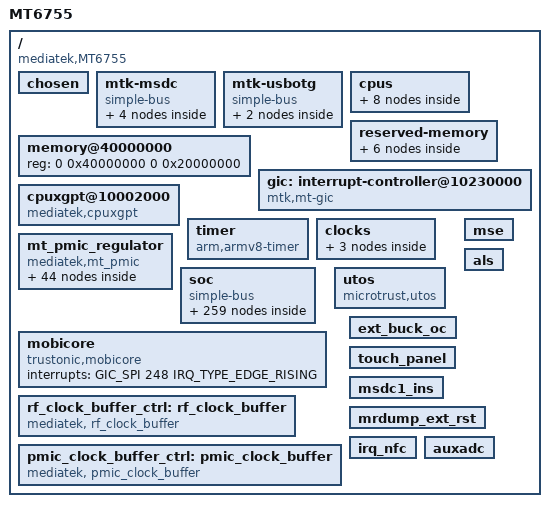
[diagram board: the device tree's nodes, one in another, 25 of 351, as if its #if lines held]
/*
 * Mediatek's MT6755 SoC device tree source
 *
 * Copyright (c) 2013 MediaTek Co., Ltd.
 *              http://www.mediatek.com
 *
 */

#include <dt-bindings/clock/mt6755-clk.h>
#include <dt-bindings/interrupt-controller/arm-gic.h>
#include <dt-bindings/interrupt-controller/irq.h>
#include "mt6755-pinfunc.h"
#include <generated/autoconf.h>

/ {
	model = "MT6755";
	compatible = "mediatek,MT6755";
	interrupt-parent = <&gic>;
	#address-cells = <2>;
	#size-cells = <2>;

	/* chosen */
	chosen {
		bootargs = "console=tty0 console=ttyMT0,921600n1 root=/dev/ram initrd=0x44000000,0x4B434E loglevel=8";
	};

	/* Do not put any bus before mtk-msdc, because it should be mtk-msdc.0 for partition device node usage */
	mtk-msdc {
		compatible = "simple-bus";
		#address-cells = <1>;
		#size-cells = <1>;
		ranges = <0 0 0 0xffffffff>;

		msdc0@11230000 {
			compatible = "mediatek,msdc0";
			reg = <0x11230000 0x10000  /* MSDC0_BASE   */
			       0x10001e84 0x2>;    /* FPGA PWR_GPIO, PWR_GPIO_EO */
			interrupts = <GIC_SPI 79 IRQ_TYPE_LEVEL_LOW>;
			clocks = <&infrasys INFRA_MSDC0>;
			clock-names = "MSDC0-CLOCK";
		};

		msdc1@11240000 {
			compatible = "mediatek,msdc1";
			reg = <0x11240000 0x10000>;
			interrupts = <GIC_SPI 80 IRQ_TYPE_LEVEL_LOW>;
			clocks = <&infrasys INFRA_MSDC1>;
			clock-names = "MSDC1-CLOCK";
		};

		msdc2@11250000 {
			compatible = "mediatek,msdc2";
			reg = <0x11250000 0x10000>;
			interrupts = <GIC_SPI 81 IRQ_TYPE_LEVEL_LOW>;
			clocks = <&infrasys INFRA_MSDC2>;
			clock-names = "MSDC2-CLOCK";
		};

		msdc3@11260000 {
			compatible = "mediatek,msdc3";
			reg = <0x11260000 0x10000>;
			interrupts = <GIC_SPI 82 IRQ_TYPE_LEVEL_LOW>;
			clocks = <&infrasys INFRA_MSDC3>;
			clock-names = "MSDC3-CLOCK";
		};

	};
	/* Do not put any bus before mtk-usbotg, because it should be mtk-usbotg.1 for partition device node usage */
	mtk-usbotg {
		compatible = "simple-bus";
		#address-cells = <1>;
		#size-cells = <1>;
		ranges = <0 0 0 0xffffffff>;
		usb3_xhci@11270000 {
			compatible = "mediatek,usb3_xhci";
			reg = <0x11270000 0x10000>, <0x11280000 0x10000>, <0x11290000 0x10000>;
			reg-names = "ssusb_base", "ssusb_sif", "ssusb_sif2";
			interrupts = <GIC_SPI 123 IRQ_TYPE_LEVEL_LOW>;
			interrupt-names = "xhci";
			eint_usb_iddig@23{
				compatible = "mediatek,usb_iddig_bi_eint";
				interrupt-parent = <&eintc>;
				interrupts = <23 IRQ_TYPE_LEVEL_LOW>;
				debounce = <23 0>;
			};
		};
	};

	cpus {
		#address-cells = <1>;
		#size-cells = <0>;

		cpu0: cpu@000 {
			device_type = "cpu";
			compatible = "arm,cortex-a53";
			reg = <0x000>;
			enable-method = "mt-boot";
			cpu-release-addr = <0x0 0x40000200>;
			clock-frequency = <1144000000>;
		};

		cpu1: cpu@001 {
			device_type = "cpu";
			compatible = "arm,cortex-a53";
			reg = <0x001>;
			enable-method = "mt-boot";
			cpu-release-addr = <0x0 0x40000200>;
			clock-frequency = <1144000000>;
		};

		cpu2: cpu@002 {
			device_type = "cpu";
			compatible = "arm,cortex-a53";
			reg = <0x002>;
			enable-method = "mt-boot";
			cpu-release-addr = <0x0 0x40000200>;
			clock-frequency = <1144000000>;
		};

		cpu3: cpu@003 {
			device_type = "cpu";
			compatible = "arm,cortex-a53";
			reg = <0x003>;
			enable-method = "mt-boot";
			cpu-release-addr = <0x0 0x40000200>;
			clock-frequency = <1144000000>;
		};
		cpu4: cpu@100 {
			device_type = "cpu";
			compatible = "arm,cortex-a53";
			reg = <0x100>;
			enable-method = "mt-boot";
			cpu-release-addr = <0x0 0x40000200>;
			clock-frequency = <1950000000>;
		};

		cpu5: cpu@101 {
			device_type = "cpu";
			compatible = "arm,cortex-a53";
			reg = <0x101>;
			enable-method = "mt-boot";
			cpu-release-addr = <0x0 0x40000200>;
			clock-frequency = <1950000000>;
		};

		cpu6: cpu@102 {
			device_type = "cpu";
			compatible = "arm,cortex-a53";
			reg = <0x102>;
			enable-method = "mt-boot";
			cpu-release-addr = <0x0 0x40000200>;
			clock-frequency = <1950000000>;
		};

		cpu7: cpu@103 {
			device_type = "cpu";
			compatible = "arm,cortex-a53";
			reg = <0x103>;
			enable-method = "mt-boot";
			cpu-release-addr = <0x0 0x40000200>;
			clock-frequency = <1950000000>;

		};
	};

	memory@40000000 {
		device_type = "memory";
		reg = <0 0x40000000 0 0x20000000>;
	};

	reserved-memory {
		#address-cells = <2>;
		#size-cells = <2>;
		ranges;

		/* reserve 256KB at DRAM start + 70MB */
		atf-reserved-memory@44600000 {
			compatible = "mediatek,mt6755-atf-reserved-memory";
			no-map;
			reg = <0 0x44600000 0 0x40000>;
		};

		reserve-memory-ccci_md1 {
			compatible = "mediatek,reserve-memory-ccci_md1";
			no-map;
			size = <0 0x8000000>; /* md_size+smem_size */
			alignment = <0 0x2000000>;
			alloc-ranges = <0 0x40000000 0 0xC0000000>;
		};

		reserve-memory-ccci_share {
			compatible = "mediatek,reserve-memory-ccci_share";
			no-map;
			size = <0 0x600000>; /* md_size+smem_size */
			alignment = <0 0x4000000>;
			alloc-ranges = <0 0x40000000 0 0xC0000000>;
		};

		consys-reserve-memory {
			compatible = "mediatek,consys-reserve-memory";
			no-map;
			size = <0 0x200000>;
			alignment = <0 0x200000>;
		};

		spm-reserve-memory {
			compatible = "mediatek,spm-reserve-memory";
			no-map;
			size = <0 0xe000>; /* PCM_FIRMWARE_SIZE * DYNA_LOAD_PCM_MAX = 8K * 7 */
			alignment = <0 0x10000>;
			alloc-ranges = <0 0x40000000 0 0x80000000>;
		};

		pstore-reserved-memory@44410000 {
			compatible = "mediatek,pstore";
			reg = <0 0x44410000 0 0xe0000>;
		};
	};

	gic: interrupt-controller@10230000 {
		compatible = "mtk,mt-gic";
		#interrupt-cells = <3>;
		#address-cells = <0>;
		interrupt-controller;
		reg = <0 0x10231000 0 0x1000>,
		      <0 0x10232000 0 0x1000>,
		      <0 0x10200620 0 0x1000>;
		interrupts = <1 9 0xf04>;

	};

	cpuxgpt@10002000 {
		compatible = "mediatek,cpuxgpt";
		reg = <0 0x10200000 0 0x1000>;
		interrupts = <GIC_SPI 64 IRQ_TYPE_LEVEL_HIGH>,
			<GIC_SPI 65 IRQ_TYPE_LEVEL_HIGH>,
			<GIC_SPI 66 IRQ_TYPE_LEVEL_HIGH>,
			<GIC_SPI 67 IRQ_TYPE_LEVEL_HIGH>,
			<GIC_SPI 68 IRQ_TYPE_LEVEL_HIGH>,
			<GIC_SPI 69 IRQ_TYPE_LEVEL_HIGH>,
			<GIC_SPI 70 IRQ_TYPE_LEVEL_HIGH>,
			<GIC_SPI 71 IRQ_TYPE_LEVEL_HIGH>;
	};

	timer {
		compatible = "arm,armv8-timer";
		interrupts = <GIC_PPI 13 IRQ_TYPE_LEVEL_LOW>,
			<GIC_PPI 14 IRQ_TYPE_LEVEL_LOW>,
			<GIC_PPI 11 IRQ_TYPE_LEVEL_LOW>,
			<GIC_PPI 10 IRQ_TYPE_LEVEL_LOW>;
			clock-frequency = <13000000>;
	};

	clocks {
		clk_null: clk_null {
			compatible = "fixed-clock";
			#clock-cells = <0>;
			clock-frequency = <0>;
		};

		clk26m: clk26m {
			compatible = "fixed-clock";
			#clock-cells = <0>;
			clock-frequency = <26000000>;
		};

		clk32k: clk32k {
			compatible = "fixed-clock";
			#clock-cells = <0>;
			clock-frequency = <32000>;
		};
	};

	mt_pmic_regulator {
		compatible = "mediatek,mt_pmic";
		/*reg = <0x01>*/
		buck_regulators {
			compatible = "mediatek,mt_pmic_buck_regulators";
			mt_pmic_vcore_buck_reg: buck_vcore {
				regulator-name = "vcore";
				regulator-min-microvolt = <600000>;
				regulator-max-microvolt = <1393750>;
				regulator-ramp-delay = <6250>;
				regulator-enable-ramp-delay = <180>;
			};
			mt_pmic_vgpu_buck_reg: buck_vgpu {
				regulator-name = "vgpu";
				regulator-min-microvolt = <600000>;
				regulator-max-microvolt = <1393750>;
				regulator-ramp-delay = <6250>;
				regulator-enable-ramp-delay = <180>;
				regulator-always-on;
				regulator-boot-on;
			};
			mt_pmic_vmodem_buck_reg: buck_vmodem {
				regulator-name = "vmodem";
				regulator-min-microvolt = <600000>;
				regulator-max-microvolt = <1393750>;
				regulator-ramp-delay = <6250>;
				regulator-enable-ramp-delay = <180>;
				regulator-always-on;
				regulator-boot-on;
			};
			mt_pmic_vmd1_buck_reg: buck_vmd1 {
				regulator-name = "vmd1";
				regulator-min-microvolt = <600000>;
				regulator-max-microvolt = <1393750>;
				regulator-ramp-delay = <6250>;
				regulator-enable-ramp-delay = <180>;
				regulator-always-on;
				regulator-boot-on;
			};
			mt_pmic_vsram_md_buck_reg: buck_vsram_md {
				regulator-name = "vsram_md";
				regulator-min-microvolt = <600000>;
				regulator-max-microvolt = <1393750>;
				regulator-ramp-delay = <6250>;
				regulator-enable-ramp-delay = <180>;
				regulator-always-on;
				regulator-boot-on;
			};
			mt_pmic_vs1_buck_reg: buck_vs1 {
				regulator-name = "vs1";
				regulator-min-microvolt = <600000>;
				regulator-max-microvolt = <1393750>;
				regulator-ramp-delay = <6250>;
				regulator-enable-ramp-delay = <180>;
				regulator-always-on;
				regulator-boot-on;
			};
			mt_pmic_vs2_buck_reg: buck_vs2 {
				regulator-name = "vs2";
				regulator-min-microvolt = <600000>;
				regulator-max-microvolt = <1393750>;
				regulator-ramp-delay = <6250>;
				regulator-enable-ramp-delay = <180>;
				regulator-always-on;
				regulator-boot-on;
			};
			mt_pmic_vpa_buck_reg: buck_vpa {
				regulator-name = "vpa";
				regulator-min-microvolt = <600000>;
				regulator-max-microvolt = <1393750>;
				regulator-ramp-delay = <6250>;
				regulator-enable-ramp-delay = <180>;
				regulator-always-on;
				regulator-boot-on;
			};
			mt_pmic_vsram_proc_buck_reg: buck_vsram_proc {
				regulator-name = "vsram_proc";
				regulator-min-microvolt = <600000>;
				regulator-max-microvolt = <1393750>;
				regulator-ramp-delay = <6250>;
				regulator-enable-ramp-delay = <180>;
				regulator-always-on;
				regulator-boot-on;
			};
		};	/* End of buck_regulators */
		ldo_regulators {
			compatible = "mediatek,mt_pmic_ldo_regulators";
			mt_pmic_va18_ldo_reg: ldo_va18 {
				regulator-name = "va18";
				regulator-min-microvolt = <1800000>;
				regulator-max-microvolt = <1800000>;
				regulator-enable-ramp-delay = <264>;
				regulator-boot-on;
			};
			mt_pmic_vtcxo24_ldo_reg: ldo_vtcxo24 {
				regulator-name = "vtcxo24";
				regulator-min-microvolt = <1800000>;
				regulator-max-microvolt = <2800000>;
				regulator-enable-ramp-delay = <110>;
				regulator-boot-on;
			};
			mt_pmic_vtcxo28_ldo_reg: ldo_vtcxo28 {
				regulator-name = "vtcxo28";
				regulator-min-microvolt = <1800000>;
				regulator-max-microvolt = <2800000>;
				regulator-enable-ramp-delay = <110>;
			};
			mt_pmic_vcn28_ldo_reg: ldo_vcn28 {
				regulator-name = "vcn28";
				regulator-min-microvolt = <1800000>;
				regulator-max-microvolt = <2800000>;
				regulator-enable-ramp-delay = <264>;
			};
			mt_pmic_vcama_ldo_reg: ldo_vcama {
				regulator-name = "vcama";
				regulator-min-microvolt = <1500000>;
				regulator-max-microvolt = <2800000>;
				regulator-enable-ramp-delay = <264>;
			};
			mt_pmic_vusb33_ldo_reg: ldo_vusb33 {
				regulator-name = "vusb33";
				regulator-min-microvolt = <3300000>;
				regulator-max-microvolt = <3300000>;
				regulator-enable-ramp-delay = <264>;
				regulator-boot-on;
			};
			mt_pmic_vsim1_ldo_reg: ldo_vsim1 {
				regulator-name = "vsim1";
				regulator-min-microvolt = <1700000>;
				regulator-max-microvolt = <3100000>;
				regulator-enable-ramp-delay = <264>;
			};
			mt_pmic_vsim2_ldo_reg: ldo_vsim2 {
				regulator-name = "vsim2";
				regulator-min-microvolt = <1700000>;
				regulator-max-microvolt = <3100000>;
				regulator-enable-ramp-delay = <264>;
			};
			mt_pmic_vemc_ldo_reg: ldo_vemc {
				regulator-name = "vemc_3v3";
				regulator-min-microvolt = <3000000>;
				regulator-max-microvolt = <3300000>;
				regulator-enable-ramp-delay = <44>;
				regulator-boot-on;
			};
			mt_pmic_vmch_ldo_reg: ldo_vmch {
				regulator-name = "vmch";
				regulator-min-microvolt = <3000000>;
				regulator-max-microvolt = <3300000>;
				regulator-enable-ramp-delay = <44>;
				regulator-boot-on;
			};
			mt_pmic_vio28_ldo_reg: ldo_vio28 {
				regulator-name = "vio28";
				regulator-min-microvolt = <2800000>;
				regulator-max-microvolt = <2800000>;
				regulator-enable-ramp-delay = <264>;
				regulator-boot-on;
			};
			mt_pmic_vibr_ldo_reg: ldo_vibr {
				regulator-name = "vibr";
				regulator-min-microvolt = <1200000>;
				regulator-max-microvolt = <3300000>;
				regulator-enable-ramp-delay = <44>;
			};
			mt_pmic_vcamd_ldo_reg: ldo_vcamd {
				regulator-name = "vcamd";
				regulator-min-microvolt = <900000>;
				regulator-max-microvolt = <1210000>;
				regulator-enable-ramp-delay = <264>;
			};
			mt_pmic_vrf18_ldo_reg: ldo_vrf18 {
				regulator-name = "vrf18";
				regulator-min-microvolt = <1000000>;
				regulator-max-microvolt = <1810000>;
				regulator-enable-ramp-delay = <220>;
			};
			mt_pmic_vio18_ldo_reg: ldo_vio18 {
				regulator-name = "vio18";
				regulator-min-microvolt = <1800000>;
				regulator-max-microvolt = <1800000>;
				regulator-enable-ramp-delay = <264>;
				regulator-boot-on;
			};
			mt_pmic_vcn18_ldo_reg: ldo_vcn18 {
				regulator-name = "vcn18";
				regulator-min-microvolt = <1800000>;
				regulator-max-microvolt = <1800000>;
				regulator-enable-ramp-delay = <44>;
			};
			mt_pmic_vcamio_ldo_reg: ldo_vcamio {
				regulator-name = "vcamio";
				regulator-min-microvolt = <1200000>;
				regulator-max-microvolt = <1800000>;
				regulator-enable-ramp-delay = <220>;
			};
			mt_pmic_vsram_proc_ldo_reg: ldo_vsram_proc {
				regulator-name = "vsram_proc";
				regulator-min-microvolt = <600000>;
				regulator-max-microvolt = <1393750>;
				regulator-enable-ramp-delay = <220>;
				regulator-boot-on;
			};
			mt_pmic_vxo22_ldo_reg: ldo_vxo22 {
				regulator-name = "vxo22";
				regulator-min-microvolt = <1800000>;
				regulator-max-microvolt = <2800000>;
				regulator-enable-ramp-delay = <110>;
				regulator-boot-on;
			};
			mt_pmic_vrf12_ldo_reg: ldo_vrf12 {
				regulator-name = "vrf12";
				regulator-min-microvolt = <900000>;
				regulator-max-microvolt = <1200000>;
				regulator-enable-ramp-delay = <220>;
			};
			mt_pmic_va10_ldo_reg: ldo_va10 {
				regulator-name = "va10";
				regulator-min-microvolt = <900000>;
				regulator-max-microvolt = <1800000>;
				regulator-enable-ramp-delay = <264>;
				regulator-boot-on;
			};
			mt_pmic_vdram_ldo_reg: ldo_vdram {
				regulator-name = "vdram";
				regulator-min-microvolt = <900000>;
				regulator-max-microvolt = <1210000>;
				regulator-enable-ramp-delay = <264>;
				regulator-boot-on;
			};
			mt_pmic_vmipi_ldo_reg: ldo_vmipi {
				regulator-name = "vmipi";
				regulator-min-microvolt = <900000>;
				regulator-max-microvolt = <1800000>;
				regulator-enable-ramp-delay = <264>;
			};
			mt_pmic_vgp3_ldo_reg: ldo_vgp3 {
				regulator-name = "vgp3";
				regulator-min-microvolt = <1000000>;
				regulator-max-microvolt = <1810000>;
				regulator-enable-ramp-delay = <264>;
			};
			mt_pmic_vbif28_ldo_reg: ldo_vbif28 {
				regulator-name = "vbif28";
				regulator-min-microvolt = <2800000>;
				regulator-max-microvolt = <2800000>;
				regulator-enable-ramp-delay = <264>;
			};
			mt_pmic_vefuse_ldo_reg: ldo_vefuse {
				regulator-name = "vefuse";
				regulator-min-microvolt = <1200000>;
				regulator-max-microvolt = <2200000>;
				regulator-enable-ramp-delay = <264>;
			};
			mt_pmic_vcn33_bt_ldo_reg: ldo_vcn33_bt {
				regulator-name = "vcn33_bt";
				regulator-min-microvolt = <3300000>;
				regulator-max-microvolt = <3600000>;
				regulator-enable-ramp-delay = <264>;
			};
			mt_pmic_vcn33_wifi_ldo_reg: ldo_vcn33_wifi {
				regulator-name = "vcn33_wifi";
				regulator-min-microvolt = <3300000>;
				regulator-max-microvolt = <3600000>;
				regulator-enable-ramp-delay = <264>;
			};
			mt_pmic_vldo28_ldo_reg: ldo_vldo28 {
				regulator-name = "vldo28";
				regulator-min-microvolt = <2800000>;
				regulator-max-microvolt = <2800000>;
				regulator-enable-ramp-delay = <264>;
			};
			mt_pmic_vmc_ldo_reg: ldo_vmc {
				regulator-name = "vmc";
				regulator-min-microvolt = <1200000>;
				regulator-max-microvolt = <3300000>;
				regulator-enable-ramp-delay = <44>;
				regulator-boot-on;
			};
			mt_pmic_vldo28_0_ldo_reg: ldo_vldo28_0 {
				regulator-name = "vldo28_0";
				regulator-min-microvolt = <2800000>;
				regulator-max-microvolt = <2800000>;
				regulator-enable-ramp-delay = <264>;
			};
			mt_pmic_vldo28_1_ldo_reg: ldo_vldo28_1 {
				regulator-name = "vldo28_1";
				regulator-min-microvolt = <2800000>;
				regulator-max-microvolt = <2800000>;
				regulator-enable-ramp-delay = <264>;
			};
		};/* End of ldo_regulators */

		regulators_supply {
			compatible = "mediatek,mt_pmic_regulator_supply";
			va18-supply = <&mt_pmic_va18_ldo_reg>;
			vtcxo24-supply = <&mt_pmic_vtcxo24_ldo_reg>;
			vtcxo28-supply = <&mt_pmic_vtcxo28_ldo_reg>;
			vsim1-supply = <&mt_pmic_vsim1_ldo_reg>;
			vsim2-supply = <&mt_pmic_vsim2_ldo_reg>;
			vemc-supply = <&mt_pmic_vemc_ldo_reg>;
			vmch-supply = <&mt_pmic_vmch_ldo_reg>;
			vmc-supply = <&mt_pmic_vmc_ldo_reg>;
			vio28-supply = <&mt_pmic_vio28_ldo_reg>;
			vibr-supply = <&mt_pmic_vibr_ldo_reg>;
			vrf18-supply = <&mt_pmic_vrf18_ldo_reg>;
			vio18-supply = <&mt_pmic_vio18_ldo_reg>;
			vsram_proc-supply = <&mt_pmic_vsram_proc_ldo_reg>;
			vxo22-supply = <&mt_pmic_vxo22_ldo_reg>;
			vrf12-supply = <&mt_pmic_vrf12_ldo_reg>;
			vdram-supply = <&mt_pmic_vdram_ldo_reg>;
			vmipi-supply = <&mt_pmic_vmipi_ldo_reg>;
			vbif28-supply = <&mt_pmic_vbif28_ldo_reg>;
			vefuse-supply = <&mt_pmic_vefuse_ldo_reg>;
		};/* End of regulators_supply */
	};/* End of mt_pmic_regulator */

	soc {
		compatible = "simple-bus";
		#address-cells = <1>;
		#size-cells = <1>;
		ranges;

		vcore_dvfs@0011cf80 {
			compatible = "mediatek,vcore_dvfs";
			reg = <0x0011cf80 0x80>;
			eint_spm_vcorefs_end@154 {
				compatible = "mediatek,spm_vcorefs_err_eint";
				interrupt-parent = <&eintc>;
				interrupts = <154 IRQ_TYPE_LEVEL_HIGH>;
				debounce = <154 0>;
			};
		};

		chipid@08000000 {
			compatible = "mediatek,chipid";
			reg = <0x08000000 0x0004>,
				<0x08000004 0x0004>,
				<0x08000008 0x0004>,
				<0x0800000c 0x0004>;
		};

		topckgen: topckgen@10000000 {
			compatible = "mediatek,mt6755-topckgen";
			reg = <0x10000000 0x1000>;
			#clock-cells = <1>;
		};

		topckgen@1000000 {
			compatible = "mediatek,topckgen";
			reg = <0x10000000 0x1000>;
		};

		scpsys: scpsys@10001000 {
			compatible = "mediatek,mt6755-scpsys";
			reg = <0x10001000 0x1000>, <0x10006000 0x1000>;
			#clock-cells = <1>;
		};

		infrasys: infrasys@10001000 {
			compatible = "mediatek,mt6755-infrasys";
			reg = <0x10001000 0x1000>;
			#clock-cells = <1>;
		};

		infracfg_ao@10001000 {
			compatible = "mediatek,infracfg_ao";
			reg = <0x10001000 0x1000>;
			interrupts = <GIC_SPI 136 IRQ_TYPE_EDGE_RISING>;
		};

		iocfg_0@10002000 {
			compatible = "mediatek,iocfg_0";
			reg = <0x10002000 0x1000>;
		};

		syscfg_pctl_a: syscfg_pctl_a@10002000 {
			compatible = "mediatek,mt6755-pctl-a-syscfg", "syscon";
			reg = <0 0x10002000 0 0x1000>;
		};

		iocfg_1@10002200 {
			compatible = "mediatek,iocfg_1";
			reg = <0x10002200 0x200>;
		};

		iocfg_2@10002400 {
			compatible = "mediatek,iocfg_2";
			reg = <0x10002400 0x200>;
		};

		iocfg_3@10002600 {
			compatible = "mediatek,iocfg_3";
			reg = <0x10002600 0x200>;
		};

		iocfg_4@10002800 {
			compatible = "mediatek,iocfg_4";
			reg = <0x10002800 0x200>;
		};

		iocfg_5@10002a00 {
			compatible = "mediatek,iocfg_5";
			reg = <0x10002a00 0x200>;
		};

		perisys: perisys@10003000 {
			compatible = "mediatek,mt6755-perisys";
			reg = <0x10003000 0x1000>;
			#clock-cells = <1>;
		};

		pericfg@10003000 {
			compatible = "mediatek,pericfg";
			reg = <0x10003000 0x1000>;
		};

		dramc0@10004000 {
			compatible = "mediatek,dramc0";
			reg = <0x10004000 0x1000>;
			interrupts = <GIC_SPI 149 IRQ_TYPE_EDGE_FALLING>;
		};

		pio: pinctrl@10005000 {
			compatible = "mediatek,mt6755-pinctrl";
			reg = <0 0x10005000 0 0x1000>;
			mediatek,pctl-regmap = <&syscfg_pctl_a>;
			gpio-controller;
			#gpio-cells = <2>;
			interrupt-controller;
			#interrupt-cells = <2>;
		};

		gpio@10005000 {
			compatible = "mediatek,gpio";
			reg = <0x10005000 0x1000>;
		};

		sleep@10006000 {
			compatible = "mediatek,sleep";
			reg = <0x10006000 0x1000>;
			interrupts = <GIC_SPI 165 IRQ_TYPE_LEVEL_LOW>,
				     <GIC_SPI 166 IRQ_TYPE_LEVEL_LOW>,
				     <GIC_SPI 167 IRQ_TYPE_LEVEL_LOW>,
				     <GIC_SPI 168 IRQ_TYPE_LEVEL_LOW>,
				     <GIC_SPI 169 IRQ_TYPE_LEVEL_LOW>,
				     <GIC_SPI 170 IRQ_TYPE_LEVEL_LOW>,
				     <GIC_SPI 171 IRQ_TYPE_LEVEL_LOW>,
				     <GIC_SPI 172 IRQ_TYPE_LEVEL_LOW>;
			clocks = <&infrasys INFRA_I2C3>;
			clock-names = "i2c3-main";
			clock-div = <10>;
			#address-cells = <1>;
			#size-cells = <0>;
			eint_spm_vcorefs_start@152 {
				compatible = "mediatek,spm_vcorefs_start_eint";
				interrupt-parent = <&eintc>;
				interrupts = <152 IRQ_TYPE_LEVEL_HIGH>;
				debounce = <152 0>;
			};

			eint_spm_vcorefs_end@153 {
				compatible = "mediatek,spm_vcorefs_end_eint";
				interrupt-parent = <&eintc>;
				interrupts = <153 IRQ_TYPE_LEVEL_HIGH>;
				debounce = <153 0>;
			};

		};

		toprgu@10007000 {
			compatible = "mediatek,toprgu";
			reg = <0x10007000 0x1000>;
			interrupts = <GIC_SPI 128 IRQ_TYPE_EDGE_FALLING>;
		};

		apxgpt@10008000 {
			compatible = "mediatek,apxgpt";
			reg = <0x10008000 0x1000>;
			interrupts = <GIC_SPI 154 IRQ_TYPE_LEVEL_LOW>;
			clock-frequency = <13000000>;
		};

		rsvd@10009000 {
			compatible = "mediatek,rsvd";
			reg = <0x10009000 0x1000>;
		};

		sej@1000a000 {
			compatible = "mediatek,hacc";
			reg = <0x1000a000 0x1000>;
			interrupts = <GIC_SPI 173 IRQ_TYPE_LEVEL_LOW>;
			clocks = <&infrasys INFRA_SEJ>;
			clock-names = "hacc-main";

		};

		eintc: eintc@1000b000 {
			compatible = "mtk,mt-eic";
			reg = <0x1000b000 0x1000>;
			interrupts = <GIC_SPI 155 IRQ_TYPE_LEVEL_HIGH>;
			max_deint_cnt = <4>;
                        deint_possible_irq = <191 192 193 194>;

			#interrupt-cells = <2>;
			interrupt-controller;

			max_eint_num = <160>;
			mapping_table_entry = <0>;
			debtime_setting_entry = <10>;
			debtime_setting_array = <0 128>,
						<1 256>,
						<2 512>,
						<3 1024>,
						<4 16384>,
						<5 32768>,
						<6 65536>,
						<7 131072>,
						<8 262144>,
						<9 524288>;

		};

		apmixedsys: apmixedsys@1000c000 {
			compatible = "mediatek,mt6755-apmixedsys";
			reg = <0x1000c000 0x1000>;
			#clock-cells = <1>;
		};

		apmixed@1000c000 {
			compatible = "mediatek,apmixed";
			reg = <0x1000c000 0xf00>;
		};

		fhctl@1000cf00 {
			compatible = "mediatek,fhctl";
			reg = <0x1000cf00 0x100>;
		};

		pwrap@1000d000 {
			compatible = "mediatek,pwrap";
			reg = <0x1000d000 0x1000>;
			interrupts = <GIC_SPI 163 IRQ_TYPE_LEVEL_HIGH>;

			pmic: mt6351 {
				compatible = "mediatek,mt6351-pmic";
				interrupt-parent = <&eintc>;
				interrupts = <150 4>;
				debounce = <150 1000>;
				interrupt-controller;
			};
		};

		devapc_ao: devapc_ao@1000e000 {
			compatible = "mediatek,devapc_ao";
			reg = <0x1000e000 0x1000>;
		};

		ddrphy@1000f000 {
			compatible = "mediatek,ddrphy";
			reg = <0x1000f000 0x1000>;
		};

		keypad: keypad@10010000 {
			compatible = "mediatek,mt6755-keypad", "mediatek,kp";
			reg = <0x10010000 0x1000>;
			interrupts = <GIC_SPI 164 IRQ_TYPE_EDGE_FALLING>;
		};

		topmisc@10011000 {
			compatible = "mediatek,topmisc";
			reg = <0x10011000 0x1000>;
		};

		mdcldma:mdcldma@10014000 {
			compatible = "mediatek,mdcldma";
			reg = 	<0x10014000 0x1e00>, /*AP_CLDMA_AO*/
				<0x10015000 0x1e00>, /*MD_CLDMA_AO*/
				<0x1021b000 0x1e00>, /*AP_CLDMA_PDN*/
				<0x1021c000 0x1e00>, /*MD_CLDMA_PDN*/
				<0x10209000 0x1000>, /*AP_CCIF_BASE*/
				<0x1020a000 0x1000>; /*MD_CCIF_BASE*/
			interrupts = <GIC_SPI 222 IRQ_TYPE_LEVEL_HIGH>, /*IRQ_CLDMA*/
				     <GIC_SPI 139 IRQ_TYPE_LEVEL_LOW>, /*IRQ_CCIF*/
				     <GIC_SPI 223 IRQ_TYPE_EDGE_FALLING>; /*IRQ_MDWDT*/
			mediatek,md_id = <0>;
			mediatek,cldma_capability = <6>;
			mediatek,md_smem_size = <0x100000>; /* md share memory size */
			clocks = <&scpsys SCP_SYS_MD1>;
			clock-names = "scp-sys-md1-main";
		};

		cpu_dbgapb {
			compatible = "mediatek,dbg_debug";
			num = <8>;
			reg =  <0x10810000 0x1000
				0x10910000 0x1000
				0x10A10000 0x1000
				0x10B10000 0x1000
				0x10C10000 0x1000
				0x10D10000 0x1000
				0x10E10000 0x1000
				0x10F10000 0x1000>;
		};

		aes_top0@10016000 {
			compatible = "mediatek,aes_top0";
			reg = <0x10016000 0x1000>;
		};

		aes_top1@10017000 {
			compatible = "mediatek,aes_top1";
			reg = <0x10017000 0x1000>;
		};

		modem_temp_share@10018000 {
			compatible = "mediatek,modem_temp_share";
			reg = <0x10018000 0x1000>;
		};

		scp_sram@10020000 {
			compatible = "mediatek,scp_sram";
			reg = <0x10020000 0x60000>;
		};

		dbgapb_base@1011a000{
			compatible = "mediatek,dbgapb_base";
			reg = <0x1011a000 0x100>;/* MD debug register */
		};

		mcucfg@10200000 {
			compatible = "mediatek,mcucfg";
			reg = <0x10200000 0x1000>;
			interrupts = <GIC_SPI 0 IRQ_TYPE_LEVEL_LOW>;
		};

		lastbus@10200000 {
			compatible = "mediatek,lastbus";
			reg = <0x10200000 0x1000>,
				<0x10003000 0x1000>;
		};

		infracfg@10201000 {
			compatible = "mediatek,infracfg";
			reg = <0x10201000 0x1000>;
		};

		sramrom@10202000 {
			compatible = "mediatek,sramrom";
			reg = <0x10202000 0x1000>;
		};

		emi@10203000 {
			compatible = "mediatek,emi";
			reg = <0x10203000 0x1000>;
			interrupts = <GIC_SPI 135 IRQ_TYPE_EDGE_FALLING>;
		};

		met_emi: met_emi@10203000 {
			compatible = "mediatek,met_emi";
			reg = <0x10203000 0x1000>;
		};

		sys_cirq@10204000 {
			compatible = "mediatek,sys_cirq";
			reg = <0x10204000 0x1000>;
			interrupts = <GIC_SPI 240 IRQ_TYPE_LEVEL_LOW>;
			cirq_num = <168>;
			spi_start_offset = <72>;
		};

		m4u@10205000 {
                        cell-index = <0>;
			compatible = "mediatek,m4u";
			reg = <0x10205000 0x1000>;
			interrupts = <GIC_SPI 147 IRQ_TYPE_LEVEL_LOW>;
			clocks = <&mmsys MM_DISP0_SMI_COMMON>,
				<&mmsys MM_DISP0_SMI_LARB0>,
				<&vdecsys VDEC0_VDEC>,
				<&vdecsys VDEC1_LARB>,
				<&imgsys IMG_IMAGE_LARB2_SMI>,
				<&vencsys VENC_VENC>,
				<&vencsys VENC_LARB>;
                        clock-names = "smi_common",
                                      "m4u_disp0_smi_larb0",
                                      "m4u_vdec0_vdec",
                                      "m4u_vdec1_larb",
                                      "m4u_img_image_larb2_smi",
                                      "m4u_venc_venc",
                                      "m4u_venc_larb";
		};

		efusec: efusec@10206000 {
			compatible = "mediatek,efusec";
			reg = <0x10206000 0x1000>;
		};

		devapc: devapc@10207000 {
			compatible = "mediatek,devapc";
			reg = <0x10207000 0x1000>;
			interrupts = <GIC_SPI 133 IRQ_TYPE_LEVEL_LOW>;
			clocks = <&infrasys INFRA_DEVICE_APC>;
			clock-names = "devapc-main";
		};

		bus_dbg@10208000 {
			compatible = "mediatek,bus_dbg";
			reg = <0x10208000 0x1000>;
			interrupts = <GIC_SPI 132 IRQ_TYPE_LEVEL_LOW>;
		};

		ap_ccif0@10209000 {
			compatible = "mediatek,ap_ccif0";
			reg = <0x10209000 0x1000>;
			interrupts = <GIC_SPI 139 IRQ_TYPE_LEVEL_LOW>;
		};

		md_ccif0@1020a000 {
			compatible = "mediatek,md_ccif0";
			reg = <0x1020a000 0x1000>;
		};

		ap_ccif1@1020b000 {
			compatible = "mediatek,ap_ccif1";
			reg = <0x1020b000 0x1000>;
			interrupts = <GIC_SPI 141 IRQ_TYPE_LEVEL_LOW>;
		};

		ap2c2k_ccif@1020b000 {
			compatible = "mediatek,ap2c2k_ccif";
			reg = <0x1020b000 0x1000>, //CCIF
			<0x10211000 0x300>, // MD1 PCCIF
			<0x10213000 0x300>; // MD3 PCCIF
			interrupts = <GIC_SPI 141 IRQ_TYPE_LEVEL_LOW>, // C2K_CCIF
			             <GIC_SPI 220 IRQ_TYPE_EDGE_FALLING>; // C2K_WDT
			cell-index = <2>;
			ccif,major = <169>;
			ccif,minor_base = <0>;
			ccif,capability = <0>;
			mediatek,md_smem_size = <0x400000>; //md share memory size
			clocks = <&scpsys SCP_SYS_MD2>;
			clock-names = "scp-sys-md2-main";
		};

		md_ccif1@1020c000 {
			compatible = "mediatek,md_ccif1";
			reg = <0x1020c000 0x1000>;
		};

		infra_mbist@1020d000 {
			compatible = "mediatek,infra_mbist";
			reg = <0x1020d000 0x1000>;
		};

		dramc_nao@1020e000 {
			compatible = "mediatek,dramc_nao";
			reg = <0x1020e000 0x1000>;
		};

		met_dramc_nao: met_dramc_nao@1020e000 {
			compatible = "mediatek,met_dramc_nao";
			reg = <0x1020e000 0x1000>;
		};

		trng@1020f000 {
			compatible = "mediatek,trng";
			reg = <0x1020f000 0x1000>;
			interrupts = <GIC_SPI 140 IRQ_TYPE_LEVEL_LOW>;
		};

		gcpu@10210000 {
			compatible = "mediatek,gcpu";
			reg = <0x10210000 0x1000>;
			interrupts = <GIC_SPI 150 IRQ_TYPE_LEVEL_LOW>;
		};

		md2md_md1_ccif0@10211000 {
			compatible = "mediatek,md2md_md1_ccif0";
			reg = <0x10211000 0x1000>;
		};

		gce@10212000 {
			compatible = "mediatek,gce";
			reg = <0x10212000 0x1000>;
			interrupts = <GIC_SPI 143 IRQ_TYPE_LEVEL_LOW>,
					<GIC_SPI 144 IRQ_TYPE_LEVEL_LOW>;
			disp_mutex_reg = <0x14014000 0x1000>;
			g3d_config_base = <0x13000000 0 0xffff0000>;
			mmsys_config_base = <0x14000000 1 0xffff0000>;
			disp_dither_base = <0x14010000 2 0xffff0000>;
			mm_na_base = <0x14020000 3 0xffff0000>;
			imgsys_base = <0x15000000 4 0xffff0000>;
			vdec_gcon_base = <0x16000000 5 0xffff0000>;
			venc_gcon_base = <0x17000000 6 0xffff0000>;
			conn_peri_base = <0x18000000 7 0xffff0000>;
			topckgen_base = <0x10000000 8 0xffff0000>;
			kp_base = <0x10010000 9 0xffff0000>;
			scp_sram_base = <0x10020000 10 0xffff0000>;
			infra_na3_base = <0x10030000 11 0xffff0000>;
			infra_na4_base = <0x10040000 12 0xffff0000>;
			scp_base = <0x10050000 13 0xffff0000>;
			mcucfg_base = <0x10200000 14 0xffff0000>;
			gcpu_base = <0x10210000 15 0xffff0000>;
			usb0_base = <0x11200000 16 0xffff0000>;
			usb_sif_base = <0x11210000 17 0xffff0000>;
			audio_base = <0x11220000 18 0xffff0000>;
			msdc0_base = <0x11230000 19 0xffff0000>;
			msdc1_base = <0x11240000 20 0xffff0000>;
			msdc2_base = <0x11250000 21 0xffff0000>;
			msdc3_base = <0x11260000 22 0xffff0000>;
			ap_dma_base = <0x11000000 23 0xffff0000>;
			mdp_rdma0_sof = <0>;
			mdp_rsz0_sof = <1>;
			mdp_rsz1_sof = <2>;
			mdp_tdshp_sof = <3>;
			mdp_wdma_sof = <4>;
			mdp_wrot_sof = <5>;
			mdp_color_sof = <6>;
			disp_ovl0_sof = <7>;
			disp_ovl1_sof = <8>;
			disp_rdma0_sof = <9>;
			disp_rdma1_sof = <10>;
			disp_wdma0_sof = <11>;
			disp_color_sof = <12>;
			disp_ccorr_sof = <13>;
			disp_aal_sof = <14>;
			disp_gamma_sof = <15>;
			disp_dither_sof = <16>;
			disp_wdma1_sof = <17>;
			disp_pwm0_sof = <18>;
			disp_2l_ovl0_sof = <19>;
			disp_2l_ovl1_sof = <20>;
			mdp_rdma0_frame_done = <21>;
			mdp_rsz0_frame_done = <22>;
			mdp_rsz1_frame_done = <23>;
			mdp_tdshp_frame_done = <24>;
			mdp_wdma_frame_done = <25>;
			mdp_wrot_write_frame_done = <26>;
			mdp_wrot_read_frame_done = <27>;
			mdp_color_frame_done = <28>;
			disp_ovl0_frame_done = <29>;
			disp_ovl1_frame_done = <30>;
			disp_rdma0_frame_done = <31>;
			disp_rdma1_frame_done = <32>;
			disp_wdma0_frame_done = <33>;
			disp_color_frame_done = <34>;
			disp_ccorr_frame_done = <35>;
			disp_aal_frame_done = <36>;
			disp_gamma_frame_done = <37>;
			disp_dither_frame_done = <38>;
			disp_dpi0_frame_done = <39>;
			disp_wdma1_frame_done = <40>;
			disp_dsi0_frame_done = <41>;
			disp_2l_ovl0_frame_done = <42>;
			disp_2l_ovl1_frame_done = <43>;
			stream_done_0 = <44>;
			stream_done_1 = <45>;
			stream_done_2 = <46>;
			stream_done_3 = <47>;
			stream_done_4 = <48>;
			stream_done_5 = <49>;
			stream_done_6 = <50>;
			stream_done_7 = <51>;
			stream_done_8 = <52>;
			stream_done_9 = <53>;
			buf_underrun_event_0 = <54>;
			buf_underrun_event_1 = <55>;
			dsi0_te_event = <56>;
			isp_frame_done_p2_2 = <129>;
			isp_frame_done_p2_1 = <130>;
			isp_frame_done_p2_0 = <131>;
			isp_frame_done_p1_1 = <132>;
			isp_frame_done_p1_0 = <133>;
			camsv_2_pass1_done = <134>;
			camsv_1_pass1_done = <135>;
			seninf_cam1_2_3_fifo_full = <136>;
			seninf_cam0_fifo_full = <137>;
			venc_done = <257>;
			jpgenc_done = <258>;
			jpgdec_done = <259>;
			venc_mb_done = <260>;
			venc_128byte_cnt_done = <261>;
			apxgpt2_count = <0x10008028>;
			clocks = <&infrasys INFRA_GCE>;
			clock-names = "GCE";
			max_prefetch_cnt = <4>;
			prefetch_size = <160 32 32 32>;
			sram_share_cnt = <1>;
			sram_share_engine = <8>;
			sram_share_event = <460>;
		};

		cqdma@10212c00 {
			compatible = "mediatek,cqdma";
			reg = <0x10212c00 0x100>,
			      <0x10212d00 0x100>;
			interrupts = <GIC_SPI 113 IRQ_TYPE_LEVEL_LOW>,
				     <GIC_SPI 114 IRQ_TYPE_LEVEL_LOW>;
			nr_channel = <2>;
		};

		md2md_md2_ccif0@10213000 {
			compatible = "mediatek,md2md_md2_ccif0";
			reg = <0x10213000 0x1000>;
		};

		mipi_tx0@10215000 {
			compatible = "mediatek,mipi_tx0";
			reg = <0x10215000 0x1000>;
		};

		mipi_rx_ana_csi0@10217000 {
			compatible = "mediatek,mipi_rx_ana_csi0";
			reg = <0x10217000 0x1000>;
		};

		mipi_rx_ana_csi1@10218000 {
			compatible = "mediatek,mipi_rx_ana_csi1";
			reg = <0x10218000 0x1000>;
		};

		gcpu_rsa@1021a000 {
			compatible = "mediatek,gcpu_rsa";
			reg = <0x1021a000 0x1000>;
		};

		infra_md@1021d000 {
			compatible = "mediatek,infra_md";
			reg = <0x1021d000 0x1000>;
		};

		bpi_bsi_slv0@1021e000 {
			compatible = "mediatek,bpi_bsi_slv0";
			reg = <0x1021e000 0x1000>;
		};

		bpi_bsi_slv1@1021f000 {
			compatible = "mediatek,bpi_bsi_slv1";
			reg = <0x1021f000 0x6000>;
		};

		bpi_bsi_slv2@10225000 {
			compatible = "mediatek,bpi_bsi_slv2";
			reg = <0x10225000 0x1000>;
		};

		emi_mpu@10226000 {
			compatible = "mediatek,emi_mpu";
			reg = <0x10226000 0x1000>;
			interrupts = <GIC_SPI 117 IRQ_TYPE_LEVEL_HIGH>;
		};

		dvfsp@10227000 {
			compatible = "mediatek,mt6755-dvfsp";
			reg = <0x10227000 0x1000>,
			      <0x0011c000 0xf80>;
			interrupts = <GIC_SPI 152 IRQ_TYPE_LEVEL_LOW>;
			clocks = <&infrasys INFRA_I2C3>;
			clock-names = "i2c";
		};

 		met_cci400@10390000 {
			compatible = "mediatek,met_cci400";
			reg = <0x10390000 0x10000>;
		};

		dbgapb@10400000 {
			compatible = "mediatek,dbgapb";
			reg = <0x10400000 0xc00000>;
			interrupts = <GIC_SPI 131 IRQ_TYPE_LEVEL_LOW>;
		};

		ap_dma@11000000 {
			compatible = "mediatek,ap_dma";
			reg = <0x11000000 0x1000>;
			interrupts = <GIC_SPI 97 IRQ_TYPE_LEVEL_LOW>;
		};

		ap_dma_uart0_tx@11000380 {
			compatible = "mediatek,ap_dma_uart0_tx";
			reg = <0x11000380 0x80>;
			interrupts = <GIC_SPI 103 IRQ_TYPE_LEVEL_LOW>;
		};

		ap_dma_uart0_rx@11000400 {
			compatible = "mediatek,ap_dma_uart0_rx";
			reg = <0x11000400 0x80>;
			interrupts = <GIC_SPI 104 IRQ_TYPE_LEVEL_LOW>;
		};

		ap_dma_uart1_tx@11000480 {
			compatible = "mediatek,ap_dma_uart1_tx";
			reg = <0x11000480 0x80>;
			interrupts = <GIC_SPI 105 IRQ_TYPE_LEVEL_LOW>;
		};

		ap_dma_uart1_rx@11000500 {
			compatible = "mediatek,ap_dma_uart1_rx";
			reg = <0x11000500 0x80>;
			interrupts = <GIC_SPI 106 IRQ_TYPE_LEVEL_LOW>;
		};

		ap_dma_btif_tx@11000780 {
			compatible = "mediatek,ap_dma_btif_tx";
			reg = <0x11000780 0x80>;
			interrupts = <GIC_SPI 111 IRQ_TYPE_LEVEL_LOW>;
		};

		ap_dma_btif_rx@11000800 {
			compatible = "mediatek,ap_dma_btif_rx";
			reg = <0x11000800 0x80>;
			interrupts = <GIC_SPI 116 IRQ_TYPE_LEVEL_LOW>;
			clocks = <&infrasys INFRA_AP_DMA>;
			clock-names = "btif-apdma-clock";
		};

		auxadc@11001000 {
			compatible = "mediatek,auxadc";
			reg = <0x11001000 0x1000>;
			interrupts = <GIC_SPI 74 IRQ_TYPE_EDGE_FALLING>;
			clocks = <&infrasys INFRA_AUXADC>;
			clock-names = "auxadc-main";
		};

		apuart0: AP_UART0@11002000 {
			cell-index = <0>;
			compatible = "mediatek,AP_UART0";
			reg = <0x11002000 0x1000>;
			interrupts = <GIC_SPI 91 IRQ_TYPE_LEVEL_LOW>;

			clock-frequency = <26000000>;
			clock-div = <1>;
			clocks = <&infrasys INFRA_UART0>, <&infrasys INFRA_AP_DMA>;
			clock-names = "uart0-main", "uart-apdma";
		};

		apuart1: AP_UART1@11003000 {
                        cell-index = <1>;
			compatible = "mediatek,AP_UART1";
			reg = <0x11003000 0x1000>;
			interrupts = <GIC_SPI 92 IRQ_TYPE_LEVEL_LOW>;

			clock-frequency = <26000000>;
			clock-div = <1>;
			clocks = <&infrasys INFRA_UART1>;
			clock-names = "uart1-main";
		};

		pwm:pwm@11006000 {
			compatible = "mediatek,pwm";
			reg = <0x11006000 0x1000>;
			interrupts = <GIC_SPI 77 IRQ_TYPE_LEVEL_LOW>;
			clocks = <&infrasys INFRA_PWM1>,
					<&infrasys INFRA_PWM2>,
					<&infrasys INFRA_PWM3>,
					<&infrasys INFRA_PWM4>,
					<&infrasys INFRA_PWM_HCLK>,
					<&infrasys INFRA_PWM>;
			clock-names = "PWM1-main",
					"PWM2-main",
					"PWM3-main",
					"PWM4-main",
					"PWM-HCLK-main",
					"PWM-main";
		};

		i2c0: i2c@11007000 {
			compatible = "mediatek,mt6755-i2c", "mediatek,i2c0";
			cell-index = <0>;
			reg = <0x11007000 0x1000>,
			      <0x11000100 0x80>;
			interrupts = <GIC_SPI 84 IRQ_TYPE_LEVEL_LOW>;
			clock-div = <10>;
			clocks = <&infrasys INFRA_I2C0>, <&infrasys INFRA_AP_DMA>;
			clock-names = "main", "dma";
			#address-cells = <1>;
			#size-cells = <0>;
		};

		i2c1: i2c@11008000 {
			compatible = "mediatek,mt6755-i2c", "mediatek,i2c1";
			cell-index = <1>;
			reg = <0x11008000 0x1000>,
			      <0x11000180 0x80>;
			interrupts = <GIC_SPI 85 IRQ_TYPE_LEVEL_LOW>;
			clock-div = <10>;
			clocks = <&infrasys INFRA_I2C1>, <&infrasys INFRA_AP_DMA>;
			clock-names = "main", "dma";
			#address-cells = <1>;
			#size-cells = <0>;
		};

		i2c2: i2c@11009000 {
			compatible = "mediatek,mt6755-i2c", "mediatek,i2c2";
			cell-index = <2>;
			reg = <0x11009000 0x1000>,
			      <0x11000200 0x80>;
			interrupts = <GIC_SPI 86 IRQ_TYPE_LEVEL_LOW>;
			clock-div = <10>;
			clocks = <&infrasys INFRA_I2C2>, <&infrasys INFRA_AP_DMA>;
			clock-names = "main", "dma";
			#address-cells = <1>;
			#size-cells = <0>;
		};

		spi0: spi@1100a000 {
			compatible = "mediatek,mt6755-spi";
			cell-index = <0>;
			spi-padmacro = <0>;
			reg = <0x1100a000 0x1000>;
			interrupts = <GIC_SPI 118 IRQ_TYPE_LEVEL_LOW>;
			clocks = <&infrasys INFRA_SPI0>;
			clock-names = "main";
			clock-frequency = <109000000>;
			clock-div = <1>;
		};

		therm_ctrl@1100b000 {
			compatible = "mediatek,mt6755-therm_ctrl";
			reg = <0x1100b000 0x1000>;
			interrupts = <GIC_SPI 78 IRQ_TYPE_LEVEL_LOW>;
			clocks = <&infrasys INFRA_THERM>, <&infrasys INFRA_AUXADC>;
			clock-names = "therm-main", "therm-auxadc";
		};

		ptp_fsm@1100b000 {
			compatible = "mediatek,mt6755-ptp_fsm";
			reg = <0x1100b000 0x1000>;
			interrupts = <GIC_SPI 125 IRQ_TYPE_LEVEL_LOW>;
			clocks = <&mfgsys MFG_BG3D>, <&scpsys SCP_SYS_MFG>, <&infrasys INFRA_THERM>;
			clock-names = "mfg-main", "mtcmos-mfg", "therm-eem";
		};

		btif@1100c000 {
			compatible = "mediatek,btif";
			reg = <0x1100c000 0x1000>;
			interrupts = <GIC_SPI 112 IRQ_TYPE_LEVEL_LOW>;
			clocks = <&infrasys INFRA_BTIF>,<&infrasys INFRA_AP_DMA>;
			clock-names = "btif-clock","btif-apdma-clock";
		};

		apirtx:irtx@1100d000 {
			compatible = "mediatek,irtx";
			reg = <0x1100d000 0x1000>;
			interrupts = <GIC_SPI 127 IRQ_TYPE_LEVEL_LOW>;
			pwm_ch = <3>;

			clock-frequency = <26000000>;
			clock-div = <1>;
			clocks = <&infrasys INFRA_IRTX>;
			clock-names = "clk-irtx-main";
		};

		disp_pwm@1100e000 {
			compatible = "mediatek,disp_pwm";
			reg = <0x1100e000 0x1000>;
		};

		i2c_appm: i2c@1100f000 {
			compatible = "mediatek,mt6755-i2c", "mediatek,i2c3";
			cell-index = <3>;
			reg = <0x1100f000 0x1000>,
			      <0x11000280 0x80>;
			interrupts = <GIC_SPI 87 IRQ_TYPE_LEVEL_LOW>;
			clock-div = <10>;
			clocks = <&infrasys INFRA_I2C3>, <&infrasys INFRA_AP_DMA>;
			clock-names = "main", "dma";
			#address-cells = <1>;
			#size-cells = <0>;

			mt6311@6b {
				compatible = "mediatek,ext_buck";
				reg = <0x6b>;
			};
		};

		spi1: spi@11010000 {
			compatible = "mediatek,mt6755-spi";
			cell-index = <1>;
			spi-padmacro = <0>;
			reg = <0x11010000 0x1000>;
			interrupts = <GIC_SPI 122 IRQ_TYPE_LEVEL_LOW>;
			clocks = <&infrasys INFRA_SPI1>;
			clock-names = "main";
			clock-frequency = <109000000>;
			clock-div = <1>;
		};

		i2c3: i2c@11011000 {
			compatible = "mediatek,mt6755-i2c", "mediatek,i2c4";
			cell-index = <4>;
			reg = <0x11011000 0x1000>,
			      <0x11000300 0x80>;
			interrupts = <GIC_SPI 88 IRQ_TYPE_LEVEL_LOW>;
			clock-div = <10>;
			clocks = <&infrasys INFRA_I2C4>, <&infrasys INFRA_AP_DMA>;
			clock-names = "main", "dma";
			#address-cells = <1>;
			#size-cells = <0>;
		};

		icusb@11200000 {
			compatible = "mediatek,icusb";
			reg = <0x11200000 0x1000>,
			      <0x11210000 0x1000>;
			interrupts = <GIC_SPI 73 IRQ_TYPE_LEVEL_LOW>;
			clocks = <&infrasys INFRA_ICUSB>, <&infrasys INFRA_SSUSB_TOP>;
			clock-names = "USB11-CLOCK", "SSUSB-CLOCK";
		};

		usb1p_sif@11210000 {
			compatible = "mediatek,usb1p_sif";
			reg = <0x11210000 0x10000>;
		};

		audiosys: audiosys@11220000 {
			compatible = "mediatek,mt6755-audiosys";
			reg = <0x11220000 0x10000>;
			#clock-cells = <1>;
		};

		audio@11220000 {
			compatible = "mediatek,audio";
			reg = <0x11220000 0x10000>;
			interrupts = <GIC_SPI 142 IRQ_TYPE_LEVEL_LOW>;
		};

		audgpio:mt_soc_dl1_pcm@11220000 {
			compatible = "mediatek,mt_soc_pcm_dl1";
			reg = <0x11220000 0x1000>;
			interrupts = <GIC_SPI 142 IRQ_TYPE_LEVEL_LOW>;
			clocks = <&audiosys AUDIO_AFE>,
				<&audiosys AUDIO_I2S>,
				<&audiosys AUDIO_DAC>,
				<&audiosys AUDIO_DAC_PREDIS>,
				<&audiosys AUDIO_ADC>,
				<&audiosys AUDIO_22M>,
				<&audiosys AUDIO_24M>,
				<&audiosys AUDIO_APLL_TUNER>,
				<&audiosys AUDIO_APLL2_TUNER>,
				<&audiosys AUDIO_TML>,
				<&audiosys AUDIO_APLL1_DIV0>,
				<&audiosys AUDIO_APLL2_DIV0>,
				<&scpsys SCP_SYS_AUD>,
				<&infrasys INFRA_AUDIO>,
				<&infrasys INFRA_AUDIO_26M_BCLK>,
				<&topckgen TOP_MUX_AUD1>,
				<&topckgen TOP_MUX_AUD2>,
				<&topckgen TOP_AD_APLL1_CK>,
				<&topckgen TOP_AD_APLL2_CK>,
				<&topckgen TOP_MUX_AUDINTBUS>,
				<&topckgen TOP_SYSPLL1_D4>,
				<&apmixedsys APMIXED_APLL1>,
				<&apmixedsys APMIXED_APLL2>,
				<&clk26m>;
			clock-names = "aud_afe_clk",
				"aud_i2s_clk",
				"aud_dac_clk",
				"aud_dac_predis_clk",
				"aud_adc_clk",
				"aud_apll22m_clk",
				"aud_apll24m_clk",
				"aud_apll1_tuner_clk",
				"aud_apll2_tuner_clk",
				"aud_tml_clk",
				"aud_apll1_div0_clk",
				"aud_apll2_div0_clk",
				"scp_sys_aud",
				"aud_infra_clk",
				"aud_peri_26m_clk",
				"aud_mux1_clk",
				"aud_mux2_clk",
				"top_ad_apll1_clk",
				"top_ad_apll2_clk",
				"top_mux_audio_int",
				"top_sys_pll1_d4",
				"apmixed_apll1_clk",
				"apmixed_apll2_clk",
				"top_clk26m_clk";
			audclk-gpio = <149 0>;
			audmosi-gpio = <150 0>;
			audmiso-gpio = <151 0>;
			vowclk-gpio = <54 0>;
			/*extspkamp-gpio = <115 0>;*/
			hpswitchtoground-gpio = <24 0>;
			i2s1clk-gpio = <80 0>;
			i2s1dat-gpio = <78 0>;
			i2s1mclk-gpio = <9 0>;
			i2s1ws-gpio = <79 0>;
		};

		mt_soc_ul1_pcm@11220000 {
			compatible = "mediatek,mt_soc_pcm_capture";
		};

		mt_soc_voice_md1@11220000 {
			compatible = "mediatek,mt_soc_pcm_voice_md1";
		};

		mt_soc_hdmi_pcm@11220000 {
			compatible = "mediatek,mt_soc_pcm_hdmi";
		};

		mt_soc_uldlloopback_pcm@11220000 {
			compatible = "mediatek,mt_soc_pcm_uldlloopback";
		};

		mt_soc_i2s0_pcm@11220000 {
			compatible = "mediatek,mt_soc_pcm_dl1_i2s0";
		};

		mt_soc_mrgrx_pcm@11220000 {
			compatible = "mediatek,mt_soc_pcm_mrgrx";
		};

		mt_soc_mrgrx_awb_pcm@11220000 {
			compatible = "mediatek,mt_soc_pcm_mrgrx_awb";
		};

		mt_soc_fm_i2s_pcm@11220000 {
			compatible = "mediatek,mt_soc_pcm_fm_i2s";
		};

		mt_soc_fm_i2s_awb_pcm@11220000 {
			compatible = "mediatek,mt_soc_pcm_fm_i2s_awb";
		};

		mt_soc_i2s0dl1_pcm@11220000 {
			compatible = "mediatek,mt_soc_pcm_dl1_i2s0Dl1";
		};

		mt_soc_dl1_awb_pcm@11220000 {
			compatible = "mediatek,mt_soc_pcm_dl1_awb";
		};

		mt_soc_voice_md1_bt@11220000 {
			compatible = "mediatek,mt_soc_pcm_voice_md1_bt";
		};

		mt_soc_voip_bt_out@11220000 {
			compatible = "mediatek,mt_soc_pcm_dl1_bt";
		};

		mt_soc_voip_bt_in@11220000 {
			compatible = "mediatek,mt_soc_pcm_bt_dai";
		};

		mt_soc_tdmrx_pcm@11220000 {
			compatible = "mediatek,mt_soc_tdm_capture";
		};

		mt_soc_fm_mrgtx_pcm@11220000 {
			compatible = "mediatek,mt_soc_pcm_fmtx";
		};

		mt_soc_ul2_pcm@11220000 {
			compatible = "mediatek,mt_soc_pcm_capture2";
		};

		mt_soc_i2s0_awb_pcm@11220000 {
			compatible = "mediatek,mt_soc_pcm_i2s0_awb";
		};

		mt_soc_voice_md2@11220000 {
			compatible = "mediatek,mt_soc_pcm_voice_md2";
		};

		mt_soc_routing_pcm@11220000 {
			compatible = "mediatek,mt_soc_pcm_routing";
			i2s1clk-gpio = <7 6>;
			i2s1dat-gpio = <5 6>;
			i2s1mclk-gpio = <9 6>;
			i2s1ws-gpio = <6 6>;
		};

		mt_soc_voice_md2_bt@11220000 {
			compatible = "mediatek,mt_soc_pcm_voice_md2_bt";
		};

		mt_soc_hp_impedance_pcm@11220000 {
			compatible = "mediatek,Mt_soc_pcm_hp_impedance";
		};

		mt_soc_codec_name@11220000 {
			compatible = "mediatek,mt_soc_codec_63xx";
		};

		mt_soc_dummy_pcm@11220000 {
			compatible = "mediatek,mt_soc_pcm_dummy";
		};

		mt_soc_codec_dummy_name@11220000 {
			compatible = "mediatek,mt_soc_codec_dummy";
		};

		mt_soc_routing_dai_name@11220000 {
			compatible = "mediatek,mt_soc_dai_routing";
		};

		mt_soc_dai_name@11220000 {
			compatible = "mediatek,mt_soc_dai_stub";
		};

		mt_soc_offload_gdma@11220000 {
			compatible = "mediatek,mt_soc_pcm_offload_gdma";
		};

		usb0p@11270000 {
			compatible = "mediatek,usb0p";
			reg = <0x11270000 0x10000>;
			interrupts = <GIC_SPI 72 IRQ_TYPE_LEVEL_LOW>;
		};

		usb3@11270000 {
			compatible = "mediatek,usb3";
			reg = <0x11270000 0x10000>, <0x11280000 0x10000>, <0x11290000 0x10000>;
			reg-names = "ssusb_base", "ssusb_sif", "ssusb_sif2";
			interrupts = <GIC_SPI 72 IRQ_TYPE_LEVEL_LOW>,
				<GIC_SPI 123 IRQ_TYPE_LEVEL_LOW>;
			interrupt-names = "musb-hdrc", "xhci";
			clocks = <&infrasys INFRA_SSUSB_TOP>;
			clock-names = "SSUSB-CLOCK";
		};

		usb3_sif@11280000 {
			compatible = "mediatek,usb3_sif";
			reg = <0x11280000 0x10000>;
		};

		usb0p_sif@11280000 {
			compatible = "mediatek,usb0p_sif";
			reg = <0x11280000 0x10000>;
		};

		usb0p_sif2@11290000 {
			compatible = "mediatek,usb0p_sif2";
			reg = <0x11290000 0x10000>;
		};

		usb3_sif2@11290000 {
			compatible = "mediatek,usb3_sif2";
			reg = <0x11290000 0x10000>;
		};

		mfgsys: mfgsys@13000000 {
			compatible = "mediatek,mt6755-mfgsys";
			reg = <0x13000000 0x1000>;
			#clock-cells = <1>;
		};

		mfg_vad@13001000 {
			compatible = "mediatek,mfg_vad";
			reg = <0x13001000 0x1000>;
		};

		mfg_dfp@13020000 {
			compatible = "mediatek,mfg_dfp";
			reg = <0x13020000 0x1000>;
		};

		mali:mali@13040000 {
			compatible = "arm,malit860", "arm,mali-t86x", "arm,malit8xx", "arm,mali-midgard";
			reg = <0x13040000 0x4000>;
			interrupts = <GIC_SPI 218 IRQ_TYPE_LEVEL_LOW>,
				<GIC_SPI 217 IRQ_TYPE_LEVEL_LOW>,
				<GIC_SPI 216 IRQ_TYPE_LEVEL_LOW>;
			interrupt-names = "JOB", "MMU", "GPU";
			clock-frequency = <700000000>;
			clocks = <&mfgsys MFG_BG3D>, <&mmsys MM_DISP0_SMI_COMMON>, <&scpsys SCP_SYS_MFG>, <&scpsys SCP_SYS_DIS>;
			clock-names = "mfg-main", "mfg-smi-common", "mtcmos-mfg", "mtcmos-display";
		};

		mmsys: mmsys@14000000 {
			compatible = "mediatek,mt6755-mmsys";
			reg = <0x14000000 0x1000>;
			#clock-cells = <1>;
		};

		mmsys_config@14000000 {
			compatible = "mediatek,mmsys_config";
			reg = <0x14000000 0x1000>;
			interrupts = <GIC_SPI 196 IRQ_TYPE_LEVEL_LOW>;
			clocks = <&mmsys MM_DISP0_CAM_MDP>;
			clock-names = "CAM_MDP";
		};

		mdp_rdma@14001000 {
			compatible = "mediatek,mdp_rdma";
			reg = <0x14001000 0x1000>;
			interrupts = <GIC_SPI 178 IRQ_TYPE_LEVEL_LOW>;
			clocks = <&mmsys MM_DISP0_MDP_RDMA>;
			clock-names = "MDP_RDMA";
		};

		mdp_rsz0@14002000 {
			compatible = "mediatek,mdp_rsz0";
			reg = <0x14002000 0x1000>;
			interrupts = <GIC_SPI 179 IRQ_TYPE_LEVEL_LOW>;
			clocks = <&mmsys MM_DISP0_MDP_RSZ0>;
			clock-names = "MDP_RSZ0";
		};

		mdp_rsz1@14003000 {
			compatible = "mediatek,mdp_rsz1";
			reg = <0x14003000 0x1000>;
			interrupts = <GIC_SPI 180 IRQ_TYPE_LEVEL_LOW>;
			clocks = <&mmsys MM_DISP0_MDP_RSZ1>;
			clock-names = "MDP_RSZ1";
		};

		mdp_wdma@14004000 {
			compatible = "mediatek,mdp_wdma";
			reg = <0x14004000 0x1000>;
			interrupts = <GIC_SPI 182 IRQ_TYPE_LEVEL_LOW>;
			clocks = <&mmsys MM_DISP0_MDP_WDMA>;
			clock-names = "MDP_WDMA";
		};

		mdp_wrot@14005000 {
			compatible = "mediatek,mdp_wrot";
			reg = <0x14005000 0x1000>;
			interrupts = <GIC_SPI 183 IRQ_TYPE_LEVEL_LOW>;
			clocks = <&mmsys MM_DISP0_MDP_WROT>;
			clock-names = "MDP_WROT";
		};

		mdp_tdshp@14006000 {
			compatible = "mediatek,mdp_tdshp";
			reg = <0x14006000 0x1000>;
			interrupts = <GIC_SPI 181 IRQ_TYPE_LEVEL_LOW>;
			clocks = <&mmsys MM_DISP0_MDP_TDSHP>;
			clock-names = "MDP_TDSHP";
		};

		mdp_color@14007000 {
			compatible = "mediatek,mdp_color";
			reg = <0x14007000 0x1000>;
			interrupts = <GIC_SPI 198 IRQ_TYPE_LEVEL_LOW>;
			clocks = <&mmsys MM_DISP0_MDP_COLOR>;
			clock-names = "MDP_COLOR";
		};

		dispsys@14008000 {
			compatible = "mediatek,dispsys";
			reg = <0x14000000 0x1000>,  /*DISP_SYS     */
			      <0x14008000 0x1000>,  /*DISP_OVL0     */
			      <0x14009000 0x1000>,  /*DISP_OVL1     */
			      <0x1400a000 0x1000>,  /*DISP_RDMA0     */
			      <0x1400b000 0x1000>,  /*DISP_RDMA1     */
			      <0x1400c000 0x1000>,  /*DISP_WDMA0     */
			      <0x1400d000 0x1000>,  /*DISP_COLOR     */
			      <0x1400e000 0x1000>,  /*DISP_CCORR     */
			      <0x1400f000 0x1000>,  /*DISP_AAL       */
			      <0x14010000 0x1000>,  /*DISP_GAMMA     */
			      <0x14011000 0x1000>,  /*DISP_DITHER    */
			      <0x14012000 0x1000>,  /*DISP_DSI0       */
			      <0x14013000 0x1000>,  /*DISP_DPI0      */
			      <0x1100e000 0x1000>,  /*DISP_PWM       */
			      <0x14014000 0x1000>,  /*DISP_MUTEX     */
			      <0x14015000 0x1000>,  /*DISP_SMI_LARB0 */
			      <0x14016000 0x1000>,  /*DISP_SMI_COMMOM*/
			      <0x14017000 0x1000>,  /*DISP_WDMA1*/
			      <0x14018000 0x1000>,  /*DISP_OVL0_2L*/
			      <0x14019000 0x1000>,  /*DISP_OVL1_2L*/
			      <0x10215000 0x1000>;      /*MIPITX0,real chip would use this:<0x14018000 0x1000>;*/


		 	interrupts = <GIC_SPI 0 IRQ_TYPE_LEVEL_LOW>, /*DISP_SYS */
					<GIC_SPI 184 IRQ_TYPE_LEVEL_LOW>, /*DISP_OVL0 */
					<GIC_SPI 185 IRQ_TYPE_LEVEL_LOW>, /*DISP_OVL1 */
					<GIC_SPI 186 IRQ_TYPE_LEVEL_LOW>, /*DISP_RDMA0 */
					<GIC_SPI 187 IRQ_TYPE_LEVEL_LOW>, /*DISP_RDMA1 */
					<GIC_SPI 188 IRQ_TYPE_LEVEL_LOW>, /*DISP_WDMA0 */
					<GIC_SPI 189 IRQ_TYPE_LEVEL_LOW>, /*DISP_COLOR */
					<GIC_SPI 190 IRQ_TYPE_LEVEL_LOW>, /*DISP_CCORR */
					<GIC_SPI 191 IRQ_TYPE_LEVEL_LOW>, /*DISP_AAL */
					<GIC_SPI 192 IRQ_TYPE_LEVEL_LOW>, /*DISP_GAMMA */
					<GIC_SPI 193 IRQ_TYPE_LEVEL_LOW>, /*DISP_DITHER */
					<GIC_SPI 194 IRQ_TYPE_LEVEL_LOW>, /*DISP_DSI0 */
					<GIC_SPI 195 IRQ_TYPE_LEVEL_LOW>, /*DISP_DPI0 */
					<GIC_SPI 0 IRQ_TYPE_LEVEL_LOW>, /*DISP_PWM */
					<GIC_SPI 177 IRQ_TYPE_LEVEL_LOW>, /*DISP_MUTEX */
					<GIC_SPI 0 IRQ_TYPE_LEVEL_LOW>, /*DISP_SMI_LARB0 */
					<GIC_SPI 0 IRQ_TYPE_LEVEL_LOW>, /*DISP_SMI_COMMOM*/
					<GIC_SPI 197 IRQ_TYPE_LEVEL_LOW>, /*DISP_WDMA1 */
					<GIC_SPI 199 IRQ_TYPE_LEVEL_LOW>, /*DISP_OVL0_2L*/
					<GIC_SPI 200 IRQ_TYPE_LEVEL_LOW>, /*DISP_OVL1_2L*/
					<GIC_SPI 0 IRQ_TYPE_LEVEL_LOW>; /*MIPITX0*/

			   clocks = <&mmsys MM_DISP0_SMI_COMMON>,
					<&mmsys MM_DISP0_SMI_LARB0>,
					<&mmsys MM_DISP0_DISP_OVL0>,
					<&mmsys MM_DISP0_DISP_OVL1>,
					<&mmsys MM_DISP0_DISP_RDMA0>,
					<&mmsys MM_DISP0_DISP_RDMA1>,
					<&mmsys MM_DISP0_DISP_WDMA0>,
					<&mmsys MM_DISP0_DISP_COLOR>,
					<&mmsys MM_DISP0_DISP_CCORR>,
					<&mmsys MM_DISP0_DISP_AAL>,
					<&mmsys MM_DISP0_DISP_GAMMA>,
					<&mmsys MM_DISP0_DISP_DITHER>,
					<&mmsys MM_DISP0_DISP_UFOE_MOUT>,
					<&mmsys MM_DISP0_DISP_WDMA1>,
					<&mmsys MM_DISP0_DISP_2L_OVL0>,
					<&mmsys MM_DISP0_DISP_2L_OVL1>,
					<&mmsys MM_DISP0_DISP_OVL0_MOUT>,
					<&mmsys MM_DISP1_DSI_ENGINE>,
					<&mmsys MM_DISP1_DSI_DIGITAL>,
					<&mmsys MM_DISP1_DPI_ENGINE>,
					<&mmsys MM_DISP1_DPI_PIXEL>,
					<&infrasys INFRA_DISP_PWM>,
					<&scpsys SCP_SYS_DIS>,
					<&topckgen TOP_MUX_DPI0>,
					<&topckgen TOP_TVDPLL_D2>,
					<&topckgen TOP_TVDPLL_D4>,
					<&topckgen TOP_TVDPLL_D8>,
					<&topckgen TOP_TVDPLL_D16>,
					<&topckgen TOP_DPI_CK>,
					<&topckgen TOP_MUX_DISPPWM>,
					<&topckgen TOP_OSC_D2>,
					<&topckgen TOP_OSC_D8>,
					<&topckgen TOP_MUX_MM>,
					<&topckgen TOP_VENCPLL_CK>,
					<&topckgen TOP_SYSPLL2_D2>;

		clock-names = "DISP0_SMI_COMMON",
					"DISP0_SMI_LARB0",
					"DISP0_DISP_OVL0",
					"DISP0_DISP_OVL1",
					"DISP0_DISP_RDMA0",
					"DISP0_DISP_RDMA1",
					"DISP0_DISP_WDMA0",
					"DISP0_DISP_COLOR",
					"DISP0_DISP_CCORR",
					"DISP0_DISP_AAL",
					"DISP0_DISP_GAMMA",
					"DISP0_DISP_DITHER",
					"DISP0_DISP_UFOE_MOUT",
					"DISP0_DISP_WDMA1",
					"DISP0_DISP_2L_OVL0",
					"DISP0_DISP_2L_OVL1",
					"DISP0_DISP_OVL0_MOUT",
					"DISP1_DSI_ENGINE",
					"DISP1_DSI_DIGITAL",
					"DISP1_DPI_ENGINE",
					"DISP1_DPI_PIXEL",
					"DISP_PWM",
					"DISP_MTCMOS_CLK",
					"MUX_DPI0",
					"TVDPLL_D2",
					"TVDPLL_D4",
					"TVDPLL_D8",
					"TVDPLL_D16",
					"DPI_CK",
					"MUX_DISPPWM",
					"OSC_D2",
					"OSC_D8",
					"MUX_MM",
					"MM_VENCPLL",
					"SYSPLL2_D2";
		};

		disp_ovl0@14008000 {
			compatible = "mediatek,disp_ovl0";
			reg = <0x14008000 0x1000>;
			interrupts = <GIC_SPI 184 IRQ_TYPE_LEVEL_LOW>;
		};

		disp_ovl1@14009000 {
			compatible = "mediatek,disp_ovl1";
			reg = <0x14009000 0x1000>;
			interrupts = <GIC_SPI 185 IRQ_TYPE_LEVEL_LOW>;
		};

		disp_rdma00@1400a000 {
			compatible = "mediatek,disp_rdma0";
			reg = <0x1400a000 0x1000>;
			interrupts = <GIC_SPI 186 IRQ_TYPE_LEVEL_LOW>;
		};

		disp_rdma1@1400b000 {
			compatible = "mediatek,disp_rdma1";
			reg = <0x1400b000 0x1000>;
			interrupts = <GIC_SPI 187 IRQ_TYPE_LEVEL_LOW>;
		};

		disp_wdma0@1400c000 {
			compatible = "mediatek,disp_wdma0";
			reg = <0x1400c000 0x1000>;
			interrupts = <GIC_SPI 188 IRQ_TYPE_LEVEL_LOW>;
		};

		disp_color@1400d000 {
			compatible = "mediatek,disp_color";
			reg = <0x1400d000 0x1000>;
			interrupts = <GIC_SPI 189 IRQ_TYPE_LEVEL_LOW>;
		};

		disp_ccorr@1400e000 {
			compatible = "mediatek,disp_ccorr";
			reg = <0x1400e000 0x1000>;
			interrupts = <GIC_SPI 190 IRQ_TYPE_LEVEL_LOW>;
		};

		disp_aal@1400f000 {
			compatible = "mediatek,disp_aal";
			reg = <0x1400f000 0x1000>;
			interrupts = <GIC_SPI 191 IRQ_TYPE_LEVEL_LOW>;
		};

		disp_gamma@14010000 {
			compatible = "mediatek,disp_gamma";
			reg = <0x14010000 0x1000>;
			interrupts = <GIC_SPI 192 IRQ_TYPE_LEVEL_LOW>;
		};

		disp_dither@14011000 {
			compatible = "mediatek,disp_dither";
			reg = <0x14011000 0x1000>;
			interrupts = <GIC_SPI 193 IRQ_TYPE_LEVEL_LOW>;
		};

		dsi0@14012000 {
			compatible = "mediatek,dsi0";
			reg = <0x14012000 0x1000>;
			interrupts = <GIC_SPI 194 IRQ_TYPE_LEVEL_LOW>;
		};

		dpi0@14013000 {
			compatible = "mediatek,dpi0";
			reg = <0x14013000 0x1000>;
			interrupts = <GIC_SPI 195 IRQ_TYPE_LEVEL_LOW>;
		};

		mm_mutex@14014000 {
			compatible = "mediatek,mm_mutex";
			reg = <0x14014000 0x1000>;
			interrupts = <GIC_SPI 177 IRQ_TYPE_LEVEL_LOW>;
		};

		smi_larb0@14015000 {
			compatible = "mediatek,smi_larb0";
			reg = <0x14015000 0x1000>;
			interrupts = <GIC_SPI 201 IRQ_TYPE_LEVEL_LOW>;
		};

		smi_common@14016000 {
			compatible = "mediatek,smi_common";
			reg = <0x14016000 0x1000>,	/* SMI_COMMON */
				<0x14015000 0x1000>,	/* LARB 0 */
				<0x16010000 0x10000>,	/* LARB 1 */
				<0x15001000 0x1000>,	/* LARB 2 */
				<0x17001000 0x1000>;	/* LARB 3 */

			clocks = <&mmsys MM_DISP0_SMI_COMMON>,
				<&mmsys MM_DISP0_SMI_LARB0>,
				<&imgsys IMG_IMAGE_LARB2_SMI>,
				<&vdecsys VDEC1_LARB>,
				<&vencsys VENC_VENC>,
				<&vencsys VENC_LARB>,
				<&scpsys SCP_SYS_VEN>,
				<&scpsys SCP_SYS_VDE>,
				<&scpsys SCP_SYS_ISP>,
				<&scpsys SCP_SYS_DIS>;

			clock-names = "smi-common", "smi-larb0", "img-larb2", "vdec1-larb", "venc-venc", "venc-larb",
			"mtcmos-ven", "mtcmos-vde", "mtcmos-isp", "mtcmos-dis";
		};

		disp_wdma1@14017000 {
			compatible = "mediatek,disp_wdma1";
			reg = <0x14017000 0x1000>;
		};

		disp_ovl0_2l@14018000 {
			compatible = "mediatek,disp_ovl0_2l";
			reg = <0x14018000 0x1000>;
			interrupts = <GIC_SPI 199 IRQ_TYPE_LEVEL_LOW>;
		};

		disp_ovl1_2l@14019000 {
			compatible = "mediatek,disp_ovl1_2l";
			reg = <0x14019000 0x1000>;
			interrupts = <GIC_SPI 200 IRQ_TYPE_LEVEL_LOW>;
		};

		imgsys: imgsys@15000000 {
			compatible = "mediatek,mt6755-imgsys";
			reg = <0x15000000 0x1000>;
			#clock-cells = <1>;
		};

		imgsys_config@15000000 {
			compatible = "mediatek,imgsys_config";
			reg = <0x15000000 0x1000>;
		};

		ispsys@15000000 {
			compatible = "mediatek,ispsys";
			reg = <0x15004000 0x9000>,  /*ISP_ADDR      */
				<0x1500D000 0x1000>,  /*INNER_ISP_ADDR      */
				<0x15000000 0x10000>,  /*IMGSYS_CONFIG_ADDR      */
				<0x10217000 0x3000>,  /*MIPI_ANA_ADDR      */
				<0x10002000 0x1000>;  /*GPIO_ADDR      */

			interrupts = <GIC_SPI 210 IRQ_TYPE_LEVEL_LOW>, /* CAM0 */
				<GIC_SPI 211 IRQ_TYPE_LEVEL_LOW>, /* CAM1 */
				<GIC_SPI 212 IRQ_TYPE_LEVEL_LOW>, /* CAM2 */
				<GIC_SPI 213 IRQ_TYPE_LEVEL_LOW>, /* CAMSV0 */
				<GIC_SPI 214 IRQ_TYPE_LEVEL_LOW>; /* CAMSV1 */

			clocks = <&scpsys SCP_SYS_DIS>,
				<&scpsys SCP_SYS_ISP>,
				<&mmsys MM_DISP0_SMI_COMMON>,
				<&imgsys IMG_IMAGE_CAM_SMI>,
				<&imgsys IMG_IMAGE_CAM_CAM>,
				<&imgsys IMG_IMAGE_SEN_TG>,
				<&imgsys IMG_IMAGE_SEN_CAM>,
				<&imgsys IMG_IMAGE_CAM_SV>,
				<&imgsys IMG_IMAGE_LARB2_SMI>;

			clock-names = "CG_SCP_SYS_DIS",
				"CG_SCP_SYS_ISP",
				"CG_DISP0_SMI_COMMON",
				"CG_IMAGE_CAM_SMI",
				"CG_IMAGE_CAM_CAM",
				"CG_IMAGE_SEN_TG",
				"CG_IMAGE_SEN_CAM",
				"CG_IMAGE_CAM_SV",
				"CG_IMAGE_LARB2_SMI";
		};

		smi_larb2@15001000 {
			compatible = "mediatek,smi_larb2";
			reg = <0x15001000 0x1000>;
			interrupts = <GIC_SPI 208 IRQ_TYPE_LEVEL_LOW>;
		};


		cam0@15004000 {
			compatible = "mediatek,cam0";
			reg = <0x15004000 0x1000>;
		};

		cam1@15005000 {
			compatible = "mediatek,cam1";
			reg = <0x15005000 0x1000>;
			interrupts = <GIC_SPI 210 IRQ_TYPE_LEVEL_LOW>;
		};

		cam2@15006000 {
			compatible = "mediatek,cam2";
			reg = <0x15006000 0x1000>;
			interrupts = <GIC_SPI 211 IRQ_TYPE_LEVEL_LOW>;
		};

		cam3@15007000 {
			compatible = "mediatek,cam3";
			reg = <0x15007000 0x1000>;
			interrupts = <GIC_SPI 212 IRQ_TYPE_LEVEL_LOW>;
		};

		kd_camera_hw1:kd_camera_hw1@15008000 {
			compatible = "mediatek,camera_hw";
			reg = <0x15008000 0x1000>;  /* SENINF_ADDR */

			/* Camera Common Clock Framework (CCF) */
			clocks = <&topckgen TOP_MUX_CAMTG>,
			<&topckgen TOP_MUX_SCAM>,
			<&topckgen TOP_UNIVPLL_D26>,
			<&topckgen TOP_UNIVPLL2_D2>;
			clock-names = "TOP_CAMTG_SEL","TOP_MUX_SCAM","TOP_UNIVPLL_D26","TOP_UNIVPLL2_D2";
			vcama-supply = <&mt_pmic_vcama_ldo_reg>;
			vcamd-supply = <&mt_pmic_vcamd_ldo_reg>;
			vcamio-supply = <&mt_pmic_vcamio_ldo_reg>;
		};

		kd_camera_hw2:kd_camera_hw2@15008000 {
			compatible = "mediatek,camera_hw2";
			reg = <0x15008000 0x1000>;  /* SENINF_ADDR */
		};

		seninf@15008000 {
			compatible = "mediatek,seninf";
			reg = <0x15008000 0x1000>;
			interrupts = <GIC_SPI 209 IRQ_TYPE_LEVEL_LOW>;
		};

		camsv@15009000 {
			compatible = "mediatek,camsv";
			reg = <0x15009000 0x1000>;
			interrupts = <GIC_SPI 213 IRQ_TYPE_LEVEL_LOW>;
		};

		fdvt@1500b000 {
			compatible = "mediatek,mt6755-fdvt";
			reg = <0x1500b000 0x1000>;
			interrupts = <GIC_SPI 215 IRQ_TYPE_LEVEL_LOW>;
			clocks = <&scpsys SCP_SYS_DIS>,
					<&scpsys SCP_SYS_ISP>,
					<&mmsys MM_DISP0_SMI_COMMON>,
					<&imgsys IMG_IMAGE_FD>;
			clock-names = "FD-SCP_SYS_DIS",
						"FD-SCP_SYS_ISP",
						"FD-MM_DISP0_SMI_COMMON",
						"FD-IMG_IMAGE_FD";
		};

		mipi_rx@1500c000 {
			compatible = "mediatek,mipi_rx";
			reg = <0x1500C000 0x1000>;
		};

		cam0_inner@1500d000 {
			compatible = "mediatek,cam0_inner";
			reg = <0x1500D000 0x1000>;
		};

		cam2_inner@1500e000 {
			compatible = "mediatek,cam2_inner";
			reg = <0x1500E000 0x1000>;
		};

		cam3_inner@1500f000 {
			compatible = "mediatek,cam3_inner";
			reg = <0x1500F000 0x1000>;
		};

		vdecsys: vdecsys@16000000 {
			compatible = "mediatek,mt6755-vdecsys";
			reg = <0x16000000 0x1000>;
			interrupts = <GIC_SPI 206 IRQ_TYPE_LEVEL_LOW>;
			#clock-cells = <1>;
		};

		vdec_gcon: vdec_gcon@16000000 {
			compatible = "mediatek,mt6755-vdec_gcon";
			reg = <0x16000000 0x1000>;
			interrupts = <GIC_SPI 206 IRQ_TYPE_LEVEL_LOW>;
			clocks = <&mmsys MM_DISP0_SMI_COMMON>, <&vdecsys VDEC0_VDEC>, <&vdecsys VDEC1_LARB>, <&vencsys VENC_VENC>, <&vencsys VENC_LARB>, <&topckgen TOP_MUX_VDEC>, <&topckgen TOP_SYSPLL1_D2>, <&topckgen TOP_SYSPLL1_D4>, <&scpsys SCP_SYS_VDE>, <&scpsys SCP_SYS_VEN>, <&scpsys SCP_SYS_DIS>;
			clock-names = "MT_CG_DISP0_SMI_COMMON", "MT_CG_VDEC0_VDEC", "MT_CG_VDEC1_LARB", "MT_CG_VENC_VENC", "MT_CG_VENC_LARB", "MT_CG_TOP_MUX_VDEC", "MT_CG_TOP_SYSPLL1_D2", "MT_CG_TOP_SYSPLL1_D4", "MT_SCP_SYS_VDE", "MT_SCP_SYS_VEN", "MT_SCP_SYS_DIS";
		};

		smi_larb1@16010000 {
			compatible = "mediatek,smi_larb1";
			reg = <0x16010000 0x10000>;
			interrupts = <GIC_SPI 207 IRQ_TYPE_LEVEL_LOW>;
		};

		vdec_full_top: vdec_full_top@16020000 {
			compatible = "mediatek,mt6755-vdec_full_top";
			reg = <0x16020000 0x10000>;
			interrupts = <GIC_SPI 206 IRQ_TYPE_LEVEL_LOW>;
		};

		vencsys: vencsys@17000000 {
			compatible = "mediatek,mt6755-vencsys";
			reg = <0x17000000 0x1000>;
			interrupts = <GIC_SPI 202 IRQ_TYPE_LEVEL_LOW>;
			#clock-cells = <1>;
		};

		venc_gcon: venc_gcon@17000000 {
			compatible = "mediatek,mt6755-venc_gcon";
			reg = <0x17000000 0x1000>;
                        interrupts = <GIC_SPI 202 IRQ_TYPE_LEVEL_LOW>;
		};

		smi_larb3@17001000 {
			compatible = "mediatek,smi_larb3";
			reg = <0x17001000 0x1000>;
			interrupts = <GIC_SPI 203 IRQ_TYPE_LEVEL_LOW>;
		};

		venc: venc@17002000 {
			compatible = "mediatek,mt6755-venc";
			reg = <0x17002000 0x1000>;
			interrupts = <GIC_SPI 202 IRQ_TYPE_LEVEL_LOW>;
		};

		jpgenc@17003000 {
			compatible = "mediatek,jpgenc";
			reg = <0x17003000 0x1000>;
			interrupts = <GIC_SPI 204 IRQ_TYPE_LEVEL_LOW>;
			clocks = <&scpsys SCP_SYS_DIS>,
			         <&mmsys MM_DISP0_SMI_COMMON>,
			         <&scpsys SCP_SYS_VEN>,
			         <&vencsys VENC_LARB_JPGENC>,
			         <&vencsys VENC_JPGENC>;

			clock-names = "disp-mtcmos",
			              "disp-smi-jpgenc",
			              "venc-mtcmos",
			              "venc-larb-jpgenc",
			              "venc-jpgenc";
		};

		jpgdec@17004000 {
			compatible = "mediatek,jpgdec";
			reg = <0x17004000 0x1000>;
			interrupts = <GIC_SPI 205 IRQ_TYPE_LEVEL_LOW>;
			clocks = <&scpsys SCP_SYS_DIS>,
			         <&mmsys MM_DISP0_SMI_COMMON>,
			         <&scpsys SCP_SYS_VEN>,
			         <&vencsys VENC_LARB_JPGDEC>,
			         <&vencsys VENC_JPGDEC>;

			clock-names = "disp-mtcmos",
			              "disp-smi-jpgdec",
			              "venc-mtcmos",
			              "venc-larb-jpgdec",
			              "venc-jpgdec";
		};

		btcvsd@18000000 {
			compatible = "mediatek,audio_bt_cvsd";
			offset =<0xF00 0x800 0xFD0 0xFD4 0xFD8>;
			/*INFRA MISC, conn_bt_cvsd_mask, cvsd_mcu_read, write, packet_indicator*/
			reg=<0x10001000 0x1000>, /*AUDIO_INFRA_BASE_PHYSICAL*/
			      <0x18000000 0x10000>, /*PKV_PHYSICAL_BASE*/
			      <0x18080000 0x8000>; /*SRAM_BANK2*/
			interrupts = <GIC_SPI 236 IRQ_TYPE_LEVEL_LOW>;
		};

		mt_soc_btcvsd_rx_pcm@18000000 {
			compatible = "mediatek,mt_soc_btcvsd_rx_pcm";
		};

		mt_soc_btcvsd_tx_pcm@18000000 {
			compatible = "mediatek,mt_soc_btcvsd_tx_pcm";
		};

		consys:consys@18070000 {
			compatible = "mediatek,mt6755-consys";
			reg = <0x18070000 0x0200>,  /*CONN_MCU_CONFIG_BASE */
			      <0x10007000 0x0100>,  /*AP_RGU_BASE */
			      <0x10000000 0x2000>,  /*TOPCKGEN_BASE */
			      <0x10006000 0x1000>;  /*SPM_BASE */
			interrupts = <GIC_SPI 237 IRQ_TYPE_LEVEL_LOW>, /*BGF_EINT */
			             <GIC_SPI 239 IRQ_TYPE_LEVEL_LOW>; /*WDT_EINT */
			clocks = <&scpsys SCP_SYS_CONN>;
			clock-names = "conn";
			/* vcn18-supply = <&mt_pmic_vcn18_ldo_reg>;
			vcn28-supply = <&mt_pmic_vcn28_ldo_reg>;
			vcn33_bt-supply = <&mt_pmic_vcn33_bt_ldo_reg>;
			vcn33_wifi-supply = <&mt_pmic_vcn33_wifi_ldo_reg>; */
		};

		wifi@180f0000 {
			compatible = "mediatek,wifi";
			reg = <0x180f0000 0x005c>;
			interrupts = <GIC_SPI 238 IRQ_TYPE_LEVEL_LOW>;
			clocks = <&infrasys INFRA_AP_DMA>;
			clock-names = "wifi-dma";
		};

		accdet: accdet {
			compatible = "mediatek, accdet";
		};

		bat_notify {
			compatible = "mediatek,bat_notify";
		};

		battery {
			compatible = "mediatek,battery";
		};

		ccci_off@0 {
			compatible = "mediatek,ccci_off";
			clocks = <&scpsys SCP_SYS_MD1>;
			clock-names = "scp-sys-md1-main";
		};

		ccci_util_cfg {
			compatible = "mediatek,ccci_util_cfg";
			mediatek,md1-smem-size = <0x200000>;
			mediatek,md3-smem-size = <0x200000>;
			mediatek,md1md3-smem-size = <0x200000>;
			mediatek,version = <0x1>;
		};

		touch: tp {
			compatible = "mediatek, touch";
			//VTOUCH-supply = <&mt_pmic_vgp1_ldo_reg>;
		};

                nfc:nfc@0 {
                        compatible = "mediatek,nfc-gpio-v2";
			gpio-ven = <28>;
			gpio-rst = <25>;
			gpio-eint = <27>;
			gpio-irq = <26>;
                };

		mt3326-gps {
			compatible = "mediatek,mt3326-gps";
		};

		hdmi@0 {
			compatible = "mediatek,sii8348-hdmi";
		};

		hwmsensor@0 {
			compatible = "mediatek,hwmsensor";
		};
		gsensor@0 {
			compatible = "mediatek,gsensor";
		};
		als_ps@0 {
			compatible = "mediatek,als_ps";
		};
		m_acc_pl@0 {
			compatible = "mediatek,m_acc_pl";
		};
		alsps:m_alsps_pl@0 {
			compatible = "mediatek,m_alsps_pl";
		};
		sensorHub@0 {
			compatible = "mediatek,sensorHub";
		};
		shf@0 {
			compatible = "mediatek,shf";
		};
		m_batch_pl@0 {
			compatible = "mediatek,m_batch_pl";
		};
		gyroscope@0 {
			compatible = "mediatek,gyroscope";
		};
		gyro:m_gyro_pl@0 {
			compatible = "mediatek,m_gyro_pl";
		};
		barometer@0 {
			compatible = "mediatek,barometer";
		};
		m_baro_pl@0 {
			compatible = "mediatek,m_baro_pl";
		};
		msensor@0 {
			compatible = "mediatek,msensor";
		};
		m_mag_pl@0 {
			compatible = "mediatek,m_mag_pl";
		};
		orientation@0 {
			compatible = "mediatek,orientation";
		};
		pedometer@0 {
			compatible = "mediatek,pedometer";
		};
		m_pdr_pl@0 {
			compatible = "mediatek,m_pdr_pl";
		};
		step_counter@0 {
			compatible = "mediatek,step_counter";
		};
		m_step_c_pl@0 {
			compatible = "mediatek,m_step_c_pl";
		};
		in_pocket@0 {
			compatible = "mediatek,in_pocket";
		};
		m_inpk_pl@0 {
			compatible = "mediatek,m_inpk_pl";
		};
		shake@0 {
			compatible = "mediatek,shake";
		};
		m_shk_pl@0 {
			compatible = "mediatek,m_shk_pl";
		};
		face_down@0 {
			compatible = "mediatek,face_down";
		};
		m_fdn_pl@0 {
			compatible = "mediatek,m_fdn_pl";
		};
		activity@0 {
			compatible = "mediatek,activity";
		};
		m_act_pl@0 {
			compatible = "mediatek,m_act_pl";
		};
		heart_rate@0 {
			compatible = "mediatek,heart_rate";
		};
		m_hrm_pl@0 {
			compatible = "mediatek,m_hrm_pl";
		};
		tilt_detector@0 {
			compatible = "mediatek,tilt_detector";
		};
		m_tilt_pl@0 {
			compatible = "mediatek,m_tilt_pl";
		};
		wake_gesture@0 {
			compatible = "mediatek,wake_gesture";
		};
		m_wag_pl@0 {
			compatible = "mediatek,m_wag_pl";
		};
		glance_gesture@0 {
			compatible = "mediatek,glance_gesture";
		};
		m_glg_pl@0 {
			compatible = "mediatek,m_glg_pl";
		};
		pick_up@0 {
			compatible = "mediatek,pick_up";
		};
		m_pkup_pl@0 {
			compatible = "mediatek,m_pkup_pl";
		};
		mtkfb: mtkfb {
			compatible = "mediatek,mtkfb";
		};
		dsi_te:dsi_te {
			compatible = "mediatek, dsi_te-eint";
		};
		swtp: swtp@ {
			compatible = "mediatek, swtp-eint";
		};
		psci {
			compatible  = "arm,psci";
			method      = "smc";
			cpu_suspend = <0x84000001>;
			cpu_off     = <0x84000002>;
			cpu_on      = <0x84000003>;
			affinity_info = <0x84000004>;
		};

		bat_metter {
			compatible = "mediatek,bat_meter";
			/* cust_charging.h */
			/* stop charging while in talking mode */
			stop_charging_in_takling = <1 >;
			talking_recharge_voltage = <3800 >;
			talking_sync_time = <60 >;

			/* Battery Temperature Protection */
			mtk_temperature_recharge_support = <1 >;
			max_charge_temperature = <50 >;
			max_charge_temperature_minus_x_degree = <47 >;
			min_charge_temperature = <0 >;
			min_charge_temperature_plus_x_degree = <6 >;
			err_charge_temperature = <0xff >;

			/* Linear Charging Threshold */
			v_pre2cc_thres = <3400 >;	/* unit: mV */
			v_cc2topoff_thres = <4050 >;
			recharging_voltage = <4110 >;
			charging_full_current = <100 >;	/* unit: mA */

			/* Charging Current Setting */
			config_usb_if = <0 >;
			usb_charger_current_suspend = <0 >;	/* Unit: 0.01 mA */
			usb_charger_current_unconfigured = <7000 >;	/* Unit: 0.01 mA */
			usb_charger_current_configured = <50000 >;	/* Unit: 0.01 mA */
			usb_charger_current = <50000 >;	/* Unit: 0.01 mA */
			ac_charger_current = <80000 >;	/* Unit: 0.01 mA */
			non_std_ac_charger_current = <50000 >;	/* Unit: 0.01 mA */
			charging_host_charger_current = <65000 >;	/* Unit: 0.01 mA */
			apple_0_5a_charger_current = <50000 >;	/* Unit: 0.01 mA */
			apple_1_0a_charger_current = <65000 >;	/* Unit: 0.01 mA */
			apple_2_1a_charger_current = <80000 >;	/* Unit: 0.01 mA */


			/* charger error check */
			bat_low_temp_protect_enable = <0 >;
			v_charger_enable = <0 >;	/* 1:on , 0:off */
			v_charger_max = <13500 >;	/* unit: mV */
			v_charger_min = <4400 >;

			/*  Tracking TIME */
			onehundred_percent_tracking_time = <10 >;	/* Unit: second */
			npercent_tracking_time = <20 >;	/* Unit: second */
			sync_to_real_tracking_time = <60 >;	/* Unit: second */
			v_0percent_tracking = <3450 >;	/* Unit: mV */

			/* High battery support */
			high_battery_voltage_support = <0 >;

			/* cust_battery_meter.h */
			/* ADC resistor  */
			r_bat_sense = <4 >;
			r_i_sense = <4 >;
			r_charger_1 = <330 >;
			r_charger_2 = <39 >;
			temperature_t0 = <110 >;
			temperature_t1 = <0 >;
			temperature_t2 = <25 >;
			temperature_t3 = <50 >;
			temperature_t = <255 >;	/* this should be fixed, never change the value */
			fg_meter_resistance = <0 >;

			/* Qmax for 0mA */
			q_max_pos_50 = <2743 >;
			q_max_pos_25 = <2709 >;
			q_max_pos_0 = <1168 >;
			q_max_neg_10 = <762 >;
			/* Qmax for 400mA, said high current */
			q_max_pos_50_h_current = <2688 >;
			q_max_pos_25_h_current = <2655 >;
			q_max_pos_0_h_current = <1145 >;
			q_max_neg_10_h_current = <747 >;
			/* Discharge percentage, 1: D5, 0: D2 */
			oam_d5 = <1 >;

			change_tracking_point = <1 >;
			/* SW OCV tracking setting */
			cust_tracking_point = <0 >;
			cust_r_sense = <56 >;
			cust_hw_cc = <0 >;
			aging_tuning_value = <103 >;
			cust_r_fg_offset = <0 >;
			ocv_board_compesate = <0 >;
			r_fg_board_base = <1000 >;
			r_fg_board_slope = <1000 >;
			car_tune_value = <118 >;

			/* HW Fuel gague  */
			current_detect_r_fg = <10 >;	/* Unit: mA */
			minerroroffset = <1000 >;
			fg_vbat_average_size = <18 >;
			r_fg_value = <10 >;	/* Unit: mOhm */

			/* HW Fuel gague 2.0*/
			difference_hwocv_rtc = <30 >;
			difference_hwocv_swocv = <10>;
			difference_swocv_rtc = <10>;
			max_swocv = <3>;

			difference_voltage_update = <20>;
			aging1_load_soc = <70>;
			aging1_update_soc = <30>;
			batterypseudo100 = <95>;
			batterypseudo1 = <6>;

			q_max_by_sys = <1>;			/*8. qmax varient by system drop voltage.*/
			q_max_sys_voltage = <3350>;
			shutdown_gauge0 = <1>;
			shutdown_gauge1_xmins = <1>;
			shutdown_gauge1_mins = <60>;

			shutdown_system_voltage = <3400>;
			charge_tracking_time = <60>;
			discharge_tracking_time = <10>;

			recharge_tolerance = <10>;

			sync_ui_soc_imm =<0>;
			mtk_enable_aging_algorithm = <1>;
			md_sleep_current_check = <1>;
			q_max_by_current = <0>;

			/* HW Fuel gague 1.0*/
			cust_poweron_delta_capacity_tolrance = <40 >;
			cust_poweron_low_capacity_tolrance = <5 >;
			cust_poweron_max_vbat_tolrance = <90 >;
			cust_poweron_delta_vbat_tolrance = <30 >;
			cust_poweron_delta_hw_sw_ocv_capacity_tolrance = <10 >;

			/* Fixed battery temperature */
			fixed_tbat_25 = <0 >;
			/* Dynamic change wake up period of battery thread when suspend */
			vbat_normal_wakeup = <3600 >;	/* Unit: mV */
			vbat_low_power_wakeup = <3500 >;	/* Unit: mV */
			normal_wakeup_period = <5400 >;	/* Unit: second */
			low_power_wakeup_period = <300 >;	/* Unit: second */
			close_poweroff_wakeup_period = <30 >;	/* Unit: second */

			rbat_pull_up_r = <24000 >;
			rbat_pull_up_volt = <2800 >;


			batt_temperature_table_num = <17 >;
			batt_temperature_table = <
			    (-20) 68237
			    (-15) 53650
			    (-10) 42506
			    (-5) 33892
			    0 27219
			    5 22021
			    10 17926
			    15 14674
			    20 12081
			    25 10000 30 8315 35 6948 40 5834 45 4917 50 4161 55 3535 60 3014 >;
			battery_profile_t0_num = <82 >;
			battery_profile_t0 = <0  4303
					6 4281
					13 4261
 	19 4240
 	27 4217
 	33 4194
 	40 4169
 	46 4145
 	54 4117
 	60 4088
 	66 4068
 	73 4047
 	79 4019
 	87 3997
 	93 3981
 	100 3967
 	106 3956
 	113 3942
 	119 3929
 	125 3913
 	133 3895
 	136 3880
 	143 3869
 	149 3857
 	155 3848
 	163 3839
 	169 3830
 	176 3823
 	182 3818
 	190 3811
 	195 3806
 	203 3800
 	209 3796
 	215 3791
 	222 3787
 	228 3781
 	236 3775
 	242 3770
 	249 3760
 	255 3752
 	263 3742
 	269 3731
 	275 3721
 	282 3713
 	288 3704
 	295 3698
 	301 3688
 	309 3665
 	315 3613
 	322 3526
 	325 3466
 	328 3444
 	331 3424
 	331 3404
 	331 3381
 	334 3357
 	334 3332
 	334 3310
 	334 3291
 	334 3274
 	334 3259
 	334 3245
 	339 3234
 	339 3221
 	339 3212
 	339 3204
 	339 3193
 	339 3186
 	339 3179
 	339 3168
 	339 3162
 	339 3157
 	339 3151
 	339 3143
 	339 3133
 	339 3125
 	339 3125
 	339 3125
 	339 3125
 	339 3125
 	339 3125
 	339 3125>;
			battery_profile_t1_num = <82 >;
			battery_profile_t1 = <0  4316
 	5 4283
 	9 4244
 	14 4210
 	16 4185
 	21 4164
 	25 4144
 	30 4128
 	35 4109
 	39 4093
 	44 4080
 	46 4069
 	51 4047
 	56 4023
 	60 4003
 	65 3989
 	68 3977
 	72 3967
 	75 3955
 	81 3940
 	86 3923
 	89 3907
 	95 3891
 	100 3877
 	102 3864
 	107 3855
 	111 3846
 	116 3837
 	119 3831
 	125 3823
 	130 3815
 	132 3811
 	137 3804
 	140 3799
 	146 3794
 	151 3790
 	154 3785
 	160 3782
 	161 3778
 	167 3773
 	170 3768
 	175 3761
 	181 3753
 	184 3742
 	188 3727
 	191 3712
 	196 3704
 	200 3701
 	205 3698
 	211 3692
 	214 3680
 	218 3625
 	221 3528
 	226 3472
 	232 3403
 	233 3323
 	233 3267
 	233 3230
 	235 3203
 	235 3180
 	235 3157
 	235 3141
 	235 3124
 	235 3109
 	235 3096
 	235 3084
 	235 3079
 	235 3067
 	235 3058
 	235 3047
 	235 3041
 	235 3032
 	235 3029
 	235 3018
 	235 3008
 	235 3002
 	235 3003
 	235 2995
 	235 2985
 	235 2983
 	235 2979
 	235 2967>;
			battery_profile_t2_num = <82 >;
			battery_profile_t2 = <0 4317
	2 4292
	3 4270
	5 4250
	8 4231
	10 4213
	11 4195
	13 4176
	15 4159
	16 4143
	18 4125
	20 4110
	23 4093
	24 4077
	26 4061
	28 4047
	29 4030
	31 4014
	33 4001
	35 3988
	37 3976
	39 3962
	41 3951
	42 3935
	44 3916
	46 3897
	48 3881
	49 3869
	52 3859
	54 3849
	55 3840
	57 3835
	59 3827
	61 3820
	62 3813
	65 3807
	67 3803
	68 3797
	70 3790
	72 3786
	74 3782
	75 3777
	77 3770
	80 3763
	81 3755
	83 3745
	85 3734
 					87 3717
	88 3699
	90 3692
	92 3690
 					94 3689
	96 3688
	98 3676
	100 3623
	101 3548
	103 3500
	105 3482
	106 3442
	109 3323
	110 3204
	110 3162
	110 3128
	111 3098
	111 3073
	111 3053
	111 3036
	111 3023
	111 3012
	111 2998
	111 2987
	111 2978
	111 2971
	111 2963
	111 2958
	111 2956
	111 2953
	111 2948
	111 2940
	111 2934
	111 2929
	111 2926>;
			battery_profile_t3_num = <82 >;
			battery_profile_t3 = <0 4331
			2 4305
			3 4284
			5 4265
			7 4244
 					10 4225
 					11 4206
 					13 4188
 					15 4170
 					16 4153
 					18 4135
 					20 4119
 					22 4102
 					23 4085
 					26 4069
 					28 4054
 					29 4038
 					31 4023
 					33 4010
 					35 3996
 					36 3984
 					38 3970
 					40 3958
 					41 3947
 					44 3934
 					46 3921
 					47 3904
 					49 3884
 					51 3868
 					53 3857
 					54 3848
 					56 3838
 					59 3832
 					60 3824
 					62 3817
 					64 3811
 					66 3806
 					67 3800
 					69 3794
 					71 3790
 					72 3784
 					74 3777
 					77 3763
 					79 3758
 					80 3750
 					82 3742
 					84 3733
 					85 3723
 					87 3709
 					89 3694
 					91 3678
 					93 3676
 					95 3675
 					97 3674
 					98 3669
 					100 3625
 					102 3547
 					104 3495
 					105 3458
 					107 3331
 					109 3140
 					109 3078
 					109 3033
 					109 3001
 					109 2980
 					110 2960
 					110 2944
 					110 2932
 					110 2921
 					110 2913
 					110 2903
 					110 2899
 					110 2889
 					110 2889
 					110 2889
 					110 2889
 					110 2889
 					110 2889
 					110 2889
 					110 2889
 					110 2889
 					110 2889>;

			r_profile_t0_num = <82 >;
			r_profile_t0 = <408 4303
			408 4281
			415 4261
			425 4240
			430 4217
			440 4194
			463 4169
			490 4145
			525 4117
			573 4088
			615 4068
			650 4047
			675 4019
			685 3997
			705 3981
			713 3967
			720 3956
			733 3942
			728 3929
			738 3913
			725 3895
			735 3880
			745 3869
			748 3857
			760 3848
			773 3839
			783 3830
			803 3823
			820 3818
			835 3811
			863 3806
			888 3800
			903 3796
			925 3791
			955 3787
			975 3781
			1000 3775
			1035 3770
			1058 3760
			1090 3752
			1105 3742
			1135 3731
			1168 3721
			1210 3713
			1255 3704
			1345 3698
			1430 3688
			1518 3665
			1570 3613
			1618 3526
			1668 3466
			1613 3444
			1563 3424
			1510 3404
			1460 3381
			1400 3357
			1333 3332
			1283 3310
			1233 3291
			1198 3274
			1155 3259
			1128 3245
			1093 3234
			1075 3221
			1053 3212
			1023 3204
			1018 3193
			1005 3186
			978 3179
			960 3168
			940 3162
			895 3157
			890 3151
			863 3143
			925 3133
			893 3125
			893 3125
			893 3125
			893 3125
			893 3125
			893 3125
			893 3125>;
			r_profile_t1_num = <82 >;
			r_profile_t1 = <258 4316
			258 4283
			278 4244
			303 4210
			333 4185
			343 4164
			350 4144
			365 4128
			370 4109
			370 4093
			380 4080
			403 4069
			395 4047
			403 4023
			403 4003
			413 3989
			418 3977
			420 3967
			423 3955
			415 3940
			410 3923
			400 3907
			393 3891
			393 3877
			388 3864
			395 3855
			403 3846
			405 3837
			415 3831
			425 3823
			430 3815
			443 3811
			450 3804
			465 3799
			475 3794
			483 3790
			490 3785
			503 3782
			520 3778
			533 3773
			545 3768
			563 3761
			588 3753
			600 3742
			608 3727
			615 3712
			635 3704
			670 3701
			710 3698
			765 3692
			840 3680
			880 3625
			915 3528
			1080 3472
			1323 3403
			1315 3323
			1180 3267
			1080 3230
			1010 3203
			958 3180
			925 3157
			888 3141
			860 3124
			810 3109
			788 3096
			765 3084
			700 3079
			745 3067
			680 3058
			685 3047
			650 3041
			683 3032
			615 3029
			643 3018
			660 3008
			635 3002
			530 3003
			640 2995
			595 2985
			535 2983
			463 2979
			600 2967>;
			r_profile_t2_num = <82 >;
			r_profile_t2 = <173 4317
			173 4292
			175 4270
			170 4250
			173 4231
			173 4213
			178 4195
			173 4176
			183 4159
			193 4143
			193 4125
			203 4110
			205 4093
			208 4077
			205 4061
			213 4047
			215 4030
			223 4014
			230 4001
			233 3988
			240 3976
			243 3962
			248 3951
			243 3935
			223 3916
			203 3897
			195 3881
			188 3869
			188 3859
			185 3849
			183 3840
			195 3835
			198 3827
			195 3820
			198 3813
			200 3807
			208 3803
			205 3797
			205 3790
			205 3786
			210 3782
			213 3777
			208 3770
			203 3763
			198 3755
			195 3745
			198 3734
			193 3717
			193 3699
			193 3692
			195 3690
			205 3689
			220 3688
			238 3676
			238 3623
			255 3548
			293 3500
			330 3482
			390 3442
			485 3323
			1018 3204
			925 3162
			838 3128
			748 3098
			720 3073
			668 3053
			608 3036
			560 3023
			550 3012
			558 2998
			538 2987
			515 2978
			485 2971
			458 2963
			455 2958
			403 2956
			398 2953
			373 2948
			373 2940
			408 2934
			420 2929
			335 2926>;
			r_profile_t3_num = <82 >;
			r_profile_t3 = <123 4331
			123 4305
			128 4284
			130 4265
			130 4244
			130 4225
			128 4206
			125 4188
			130 4170
			133 4153
			133 4135
			138 4119
			138 4102
			140 4085
			140 4069
			143 4054
			140 4038
			143 4023
			148 4010
			153 3996
			155 3984
			155 3970
			165 3958
			175 3947
			175 3934
			178 3921
			170 3904
			148 3884
			135 3868
			135 3857
			133 3848
			133 3838
			135 3832
			135 3824
			135 3817
			143 3811
			145 3806
			148 3800
			145 3794
			153 3790
			150 3784
			150 3777
			133 3763
			143 3758
			140 3750
			138 3742
			135 3733
			135 3723
			133 3709
			133 3694
			130 3678
			130 3676
			138 3675
			148 3674
			160 3669
			158 3625
			170 3547
			208 3495
			220 3458
			265 3331
			855 3140
			725 3078
			600 3033
			528 3001
			460 2980
			400 2960
			380 2944
			355 2932
			315 2921
			303 2913
			308 2903
			255 2899
			273 2889
			273 2889
			273 2889
			273 2889
			273 2889
			273 2889
			273 2889
			273 2889
			273 2889
			273 2889>;
        };
	}; /* soc */

	mobicore {
		compatible = "trustonic,mobicore";
		interrupts = <GIC_SPI 248 IRQ_TYPE_EDGE_RISING>;
	};

	utos {
			compatible = "microtrust,utos";
			interrupts = <GIC_SPI 244 IRQ_TYPE_EDGE_RISING>,
			<GIC_SPI 245 IRQ_TYPE_EDGE_RISING>,
			<GIC_SPI 246 IRQ_TYPE_EDGE_RISING>,
			<GIC_SPI 250 IRQ_TYPE_EDGE_RISING>,
			<GIC_SPI 251 IRQ_TYPE_EDGE_RISING>,
			<GIC_SPI 252 IRQ_TYPE_EDGE_RISING>,
			<GIC_SPI 253 IRQ_TYPE_EDGE_RISING>,
			<GIC_SPI 255 IRQ_TYPE_EDGE_RISING>;
	};

	rf_clock_buffer_ctrl:rf_clock_buffer {
		compatible = "mediatek, rf_clock_buffer";
		buffer1 = <2>;
		buffer2 = <0>;
		buffer3 = <1>;
		buffer4 = <1>;
		mediatek,clkbuf-driving-current = <2 2 2 2>;
	};

	pmic_clock_buffer_ctrl:pmic_clock_buffer {
		compatible = "mediatek, pmic_clock_buffer";
		buffer1 = <2>;
		buffer2 = <1>;
		buffer3 = <1>;
		buffer4 = <2>;
		mediatek,clkbuf-driving-current = <2 2 2 2>;
	};

	ext_buck_oc: ext_buck_oc {
        };

	touch_panel: touch_panel {
	};
	msdc1_ins: msdc1_ins {
	};
	mse: mse {
	};
	als: als {
	};
	mrdump_ext_rst: mrdump_ext_rst {
	};
	irq_nfc: irq_nfc {
	};
	auxadc: auxadc {
	};

};

#ifdef CONFIG_MTK_LEGACY
/include/ "cust_eint.dtsi"
/include/ "cust_i2c.dtsi"
/include/ "cust_kpd.dtsi"
/*/include/ "cust_pmic.dtsi"*/
/include/ "cust_clk_buf.dtsi"
/include/ "cust_md1_eint.dtsi"
#else
#include "cust.dtsi"
#endif
